VERSION ""

NS_ :

BS_:

BU_: XXX

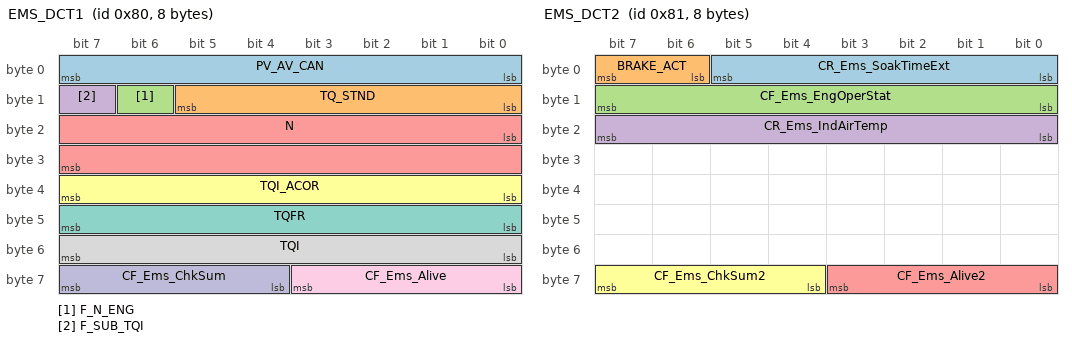
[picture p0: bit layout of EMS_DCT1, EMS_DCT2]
BO_ 128 EMS_DCT1: 8 XXX
    SG_ PV_AV_CAN : 0|8@1+ (0.3906,0) [0|99.603] "%" XXX
    SG_ TQ_STND : 8|6@1+ (10,0) [0|630] "Nm" XXX
    SG_ F_N_ENG : 14|1@1+ (1,0) [0|1] "" XXX
    SG_ F_SUB_TQI : 15|1@1+ (1,0) [0|1] "" XXX
    SG_ N : 16|16@1+ (0.25,0) [0|16383.8] "rpm" XXX
    SG_ TQI_ACOR : 32|8@1+ (0.390625,0) [0|99.6094] "%" XXX
    SG_ TQFR : 40|8@1+ (0.390625,0) [0|99.6094] "%" XXX
    SG_ TQI : 48|8@1+ (0.390625,0) [0|99.6094] "%" XXX
    SG_ CF_Ems_Alive : 56|4@1+ (1,0) [0|15] "" XXX
    SG_ CF_Ems_ChkSum : 60|4@1+ (1,0) [0|15] "" XXX

BO_ 129 EMS_DCT2: 8 XXX
    SG_ CR_Ems_SoakTimeExt : 0|6@1+ (5,0) [0|315] "Min" XXX
    SG_ BRAKE_ACT : 6|2@1+ (1,0) [0|3] "" XXX
    SG_ CF_Ems_EngOperStat : 8|8@1+ (1,0) [0|255] "" XXX
    SG_ CR_Ems_IndAirTemp : 16|8@1+ (0.75,-48) [-48|143.25] "" XXX
    SG_ CF_Ems_Alive2 : 56|4@1+ (1,0) [0|15] "" XXX
    SG_ CF_Ems_ChkSum2 : 60|4@1+ (1,0) [0|15] "" XXX

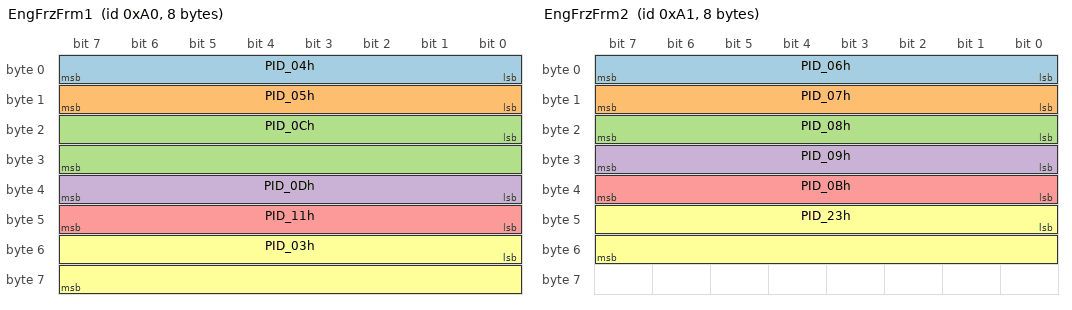
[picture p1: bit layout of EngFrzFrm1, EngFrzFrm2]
BO_ 160 EngFrzFrm1: 8 XXX
    SG_ PID_04h : 0|8@1+ (0.392157,0) [0|100] "%" XXX
    SG_ PID_05h : 8|8@1+ (1,-40) [-40|215] "" XXX
    SG_ PID_0Ch : 16|16@1+ (0.25,0) [0|16383.8] "rpm" XXX
    SG_ PID_0Dh : 32|8@1+ (1,0) [0|255] "km/h" XXX
    SG_ PID_11h : 40|8@1+ (0.392157,0) [0|100] "%" XXX
    SG_ PID_03h : 48|16@1+ (1,0) [0|65535] "" XXX

BO_ 161 EngFrzFrm2: 8 XXX
    SG_ PID_06h : 0|8@1+ (0.78125,-100) [-100|99.22] "%" XXX
    SG_ PID_07h : 8|8@1+ (0.78125,-100) [-100|99.22] "%" XXX
    SG_ PID_08h : 16|8@1+ (0.78125,-100) [-100|99.22] "%" XXX
    SG_ PID_09h : 24|8@1+ (0.78125,-100) [-100|99.22] "%" XXX
    SG_ PID_0Bh : 32|8@1+ (1,0) [0|255] "kPa" XXX
    SG_ PID_23h : 40|16@1+ (10,0) [0|655350] "kPa" XXX

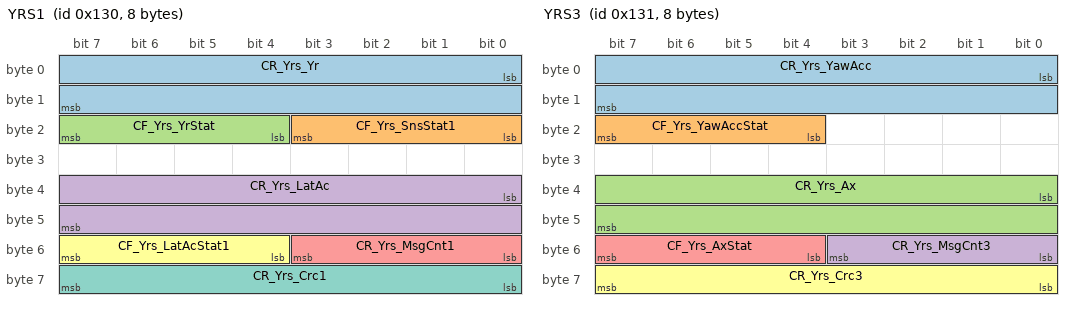
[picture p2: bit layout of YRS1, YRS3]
BO_ 304 YRS1: 8 XXX
    SG_ CR_Yrs_Yr : 0|16@1+ (0.005,-163.84) [-163.84|163.83] "" XXX
    SG_ CF_Yrs_SnsStat1 : 16|4@1+ (1,0) [0|15] "" XXX
    SG_ CF_Yrs_YrStat : 20|4@1+ (1,0) [0|15] "" XXX
    SG_ CR_Yrs_LatAc : 32|16@1+ (0.000127465,-4.17677) [-4.17677|4.17652] "g" XXX
    SG_ CR_Yrs_MsgCnt1 : 48|4@1+ (1,0) [0|15] "" XXX
    SG_ CF_Yrs_LatAcStat1 : 52|4@1+ (1,0) [0|15] "" XXX
    SG_ CR_Yrs_Crc1 : 56|8@1+ (1,0) [0|255] "" XXX

BO_ 305 YRS3: 8 XXX
    SG_ CR_Yrs_YawAcc : 0|16@1+ (0.125,-4096) [-4096|4095.75] "" XXX
    SG_ CF_Yrs_YawAccStat : 20|4@1+ (1,0) [0|15] "" XXX
    SG_ CR_Yrs_Ax : 32|16@1+ (0.000127465,-4.17677) [-4.17677|4.17652] "g" XXX
    SG_ CR_Yrs_MsgCnt3 : 48|4@1+ (1,0) [0|15] "" XXX
    SG_ CF_Yrs_AxStat : 52|4@1+ (1,0) [0|15] "" XXX
    SG_ CR_Yrs_Crc3 : 56|8@1+ (1,0) [0|255] "" XXX

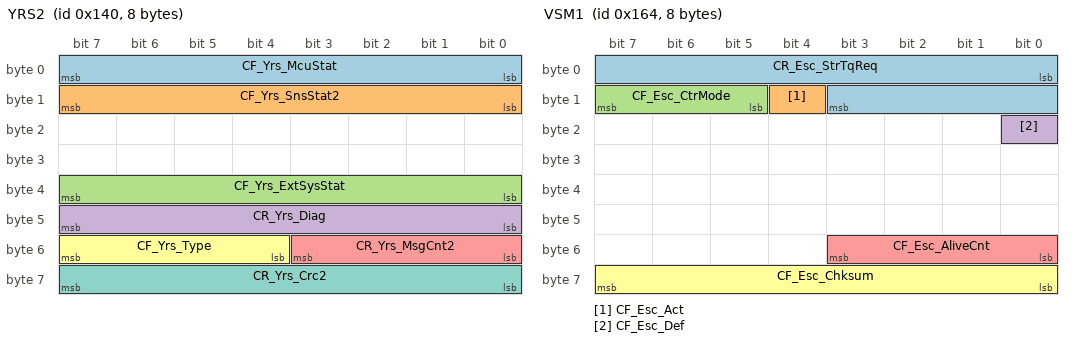
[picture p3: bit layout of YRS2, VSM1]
BO_ 320 YRS2: 8 XXX
    SG_ CF_Yrs_McuStat : 0|8@1+ (1,0) [0|255] "" XXX
    SG_ CF_Yrs_SnsStat2 : 8|8@1+ (1,0) [0|255] "" XXX
    SG_ CF_Yrs_ExtSysStat : 32|8@1+ (1,0) [0|255] "" XXX
    SG_ CR_Yrs_Diag : 40|8@1+ (1,0) [0|255] "" XXX
    SG_ CR_Yrs_MsgCnt2 : 48|4@1+ (1,0) [0|15] "" XXX
    SG_ CF_Yrs_Type : 52|4@1+ (1,0) [0|15] "" XXX
    SG_ CR_Yrs_Crc2 : 56|8@1+ (1,0) [0|255] "" XXX

BO_ 339 TCS1: 8 XXX
    SG_ TCS_REQ : 0|1@1+ (1,0) [0|1] "" XXX
    SG_ MSR_C_REQ : 1|1@1+ (1,0) [0|1] "" XXX
    SG_ TCS_PAS : 2|1@1+ (1,0) [0|1] "" XXX
    SG_ TCS_GSC : 3|1@1+ (1,0) [0|1] "" XXX
    SG_ CF_Esc_LimoInfo : 4|2@1+ (1,0) [0|3] "" XXX
    SG_ ABS_DIAG : 6|1@1+ (1,0) [0|1] "" XXX
    SG_ ABS_DEF : 7|1@1+ (1,0) [0|1] "" XXX
    SG_ TCS_DEF : 8|1@1+ (1,0) [0|1] "" XXX
    SG_ TCS_CTL : 9|1@1+ (1,0) [0|1] "" XXX
    SG_ ABS_ACT : 10|1@1+ (1,0) [0|1] "" XXX
    SG_ EBD_DEF : 11|1@1+ (1,0) [0|1] "" XXX
    SG_ ESP_PAS : 12|1@1+ (1,0) [0|1] "" XXX
    SG_ ESP_DEF : 13|1@1+ (1,0) [0|1] "" XXX
    SG_ ESP_CTL : 14|1@1+ (1,0) [0|1] "" XXX
    SG_ TCS_MFRN : 15|1@1+ (1,0) [0|1] "" XXX
    SG_ DBC_CTL : 16|1@1+ (1,0) [0|1] "" XXX
    SG_ DBC_PAS : 17|1@1+ (1,0) [0|1] "" XXX
    SG_ DBC_DEF : 18|1@1+ (1,0) [0|1] "" XXX
    SG_ HAC_CTL : 19|1@1+ (1,0) [0|1] "" XXX
    SG_ HAC_PAS : 20|1@1+ (1,0) [0|1] "" XXX
    SG_ HAC_DEF : 21|1@1+ (1,0) [0|1] "" XXX
    SG_ ESS_STAT : 22|2@1+ (1,0) [0|3] "" XXX
    SG_ TQI_TCS : 24|8@1+ (0.390625,0) [0|99.6094] "%" XXX
    SG_ TQI_MSR : 32|8@1+ (0.390625,0) [0|99.6094] "%" XXX
    SG_ TQI_SLW_TCS : 40|8@1+ (0.390625,0) [0|99.6094] "%" XXX
    SG_ CF_Esc_BrkCtl : 48|1@1+ (1,0) [0|1] "" XXX
    SG_ ESC_OFF_STEP : 49|2@1+ (1,0) [0|3] "" XXX
    SG_ _4WD_Status : 51|1@1+ (1,0) [0|1] "" XXX
    SG_ AliveCounter_TCS1 : 52|4@1+ (1,0) [0|1] "" XXX
    SG_ CheckSum_TCS1 : 56|8@1+ (1,0) [0|1] "" XXX

BO_ 356 VSM1: 8 XXX
    SG_ CR_Esc_StrTqReq : 0|12@1+ (0.01,-20.48) [-20.48|20.47] "Nm" XXX
    SG_ CF_Esc_Act : 12|1@1+ (1,0) [0|1] "" XXX
    SG_ CF_Esc_CtrMode : 13|3@1+ (1,0) [0|7] "" XXX
    SG_ CF_Esc_Def : 16|1@1+ (1,0) [0|1] "" XXX
    SG_ CF_Esc_AliveCnt : 48|4@1+ (1,0) [0|15] "" XXX
    SG_ CF_Esc_Chksum : 56|8@1+ (1,0) [0|255] "" XXX

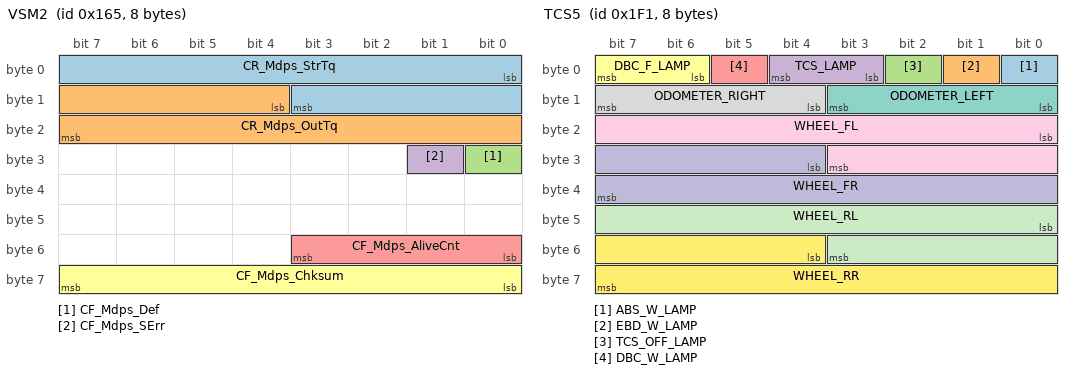
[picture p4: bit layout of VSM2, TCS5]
BO_ 357 VSM2: 8 XXX
    SG_ CR_Mdps_StrTq : 0|12@1+ (0.01,-20.48) [-20.48|20.47] "Nm" XXX
    SG_ CR_Mdps_OutTq : 12|12@1+ (0.1,-204.8) [-204.8|204.7] "" XXX
    SG_ CF_Mdps_Def : 24|1@1+ (1,0) [0|1] "" XXX
    SG_ CF_Mdps_SErr : 25|1@1+ (1,0) [0|1] "" XXX
    SG_ CF_Mdps_AliveCnt : 48|4@1+ (1,0) [0|15] "" XXX
    SG_ CF_Mdps_Chksum : 56|8@1+ (1,0) [0|255] "" XXX

BO_ 399 EMS_H2: 8 XXX
    SG_ R_TqAcnApvC : 0|8@1+ (0.2,0) [0|51] "Nm" XXX
    SG_ R_PAcnC : 8|8@1+ (125,0) [0|31875] "hPa" XXX
    SG_ TQI_B : 16|8@1+ (0.390625,0) [0|99.6094] "%" XXX
    SG_ SLD_VS : 24|8@1+ (1,0) [0|255] "km/h" XXX
    SG_ CF_CdaStat : 32|3@1+ (1,0) [0|7] "" XXX
    SG_ CF_Ems_IsgStat : 35|3@1+ (1,0) [0|7] "" XXX
    SG_ CF_Ems_OilChg : 38|1@1+ (1,0) [0|1] "" XXX
    SG_ CF_Ems_EtcLimpMod : 39|1@1+ (1,0) [0|1] "" XXX
    SG_ R_NEngIdlTgC : 40|8@1+ (10,0) [0|2550] "rpm" XXX
    SG_ CF_Ems_UpTarGr : 48|1@1+ (1,0) [0|1] "" XXX
    SG_ CF_Ems_DownTarGr : 49|1@1+ (1,0) [0|1] "" XXX
    SG_ CF_Ems_DesCurGr : 50|4@1+ (1,0) [0|15] "" XXX
    SG_ CF_Ems_SldAct : 54|1@1+ (1,0) [0|1] "" XXX
    SG_ CF_Ems_SldPosAct : 55|1@1+ (1,0) [0|1] "" XXX
    SG_ CF_Ems_HPresStat : 56|1@1+ (1,0) [0|1] "" XXX
    SG_ CF_Ems_IsgBuz : 57|1@1+ (1,0) [0|1] "" XXX
    SG_ CF_Ems_IdlStpFCO : 58|1@1+ (1,0) [0|1] "" XXX
    SG_ CF_Ems_FCopen : 59|1@1+ (1,0) [0|1] "" XXX
    SG_ CF_Ems_ActEcoAct : 60|1@1+ (1,0) [0|1] "" XXX
    SG_ CF_Ems_EngRunNorm : 61|1@1+ (1,0) [0|1] "" XXX
    SG_ CF_Ems_IsgStat2 : 62|2@1+ (2,0) [0|3] "" XXX

BO_ 497 TCS5: 8 XXX
    SG_ ABS_W_LAMP : 0|1@1+ (1,0) [0|1] "" XXX
    SG_ EBD_W_LAMP : 1|1@1+ (1,0) [0|1] "" XXX
    SG_ TCS_OFF_LAMP : 2|1@1+ (1,0) [0|1] "" XXX
    SG_ TCS_LAMP : 3|2@1+ (1,0) [0|3] "" XXX
    SG_ DBC_W_LAMP : 5|1@1+ (1,0) [0|1] "" XXX
    SG_ DBC_F_LAMP : 6|2@1+ (1,0) [0|3] "" XXX
    SG_ ODOMETER_LEFT : 8|4@1+ (1,0) [0|15] "m" XXX
    SG_ ODOMETER_RIGHT : 12|4@1+ (1,0) [0|15] "m" XXX
    SG_ WHEEL_FL : 16|12@1+ (0.125,0) [0|511.875] "km/h" XXX
    SG_ WHEEL_FR : 28|12@1+ (0.125,0) [0|511.875] "km/h" XXX
    SG_ WHEEL_RL : 40|12@1+ (0.125,0) [0|511.875] "km/h" XXX
    SG_ WHEEL_RR : 52|12@1+ (0.125,0) [0|511.875] "km/h" XXX

BO_ 544 ESP2: 8 XXX
    SG_ LAT_ACCEL : 0|11@1+ (0.01,-10.23) [-10.23|10.24] "m/s^2" XXX
    SG_ ESP2_AliveCounter_LSB : 11|3@1+ (1,0) [0|7] "" XXX
    SG_ LAT_ACCEL_STAT : 14|1@1+ (1,0) [0|1] "" XXX
    SG_ LAT_ACCEL_DIAG : 15|1@1+ (1,0) [0|1] "" XXX
    SG_ LONG_ACCEL : 16|11@1+ (0.01,-10.23) [-10.23|10.24] "m/s^2" XXX
    SG_ ESP2_AliveCounter_MSB : 27|1@1+ (1,0) [0|1] "" XXX
    SG_ ESP2_Checksum_LSB : 28|2@1+ (1,0) [0|3] "" XXX
    SG_ LONG_ACCEL_STAT : 30|1@1+ (1,0) [0|1] "" XXX
    SG_ LONG_ACCEL_DIAG : 31|1@1+ (1,0) [0|1] "" XXX
    SG_ CYL_PRES : 32|12@1+ (0.1,0) [0|409.5] "Bar" XXX
    SG_ ESP12_Checksum_MSB : 44|2@1+ (1,0) [0|3] "" XXX
    SG_ CYL_PRES_STAT : 46|1@1+ (1,0) [0|1] "" XXX
    SG_ CYL_PRESS_DIAG : 47|1@1+ (1,0) [0|1] "" XXX
    SG_ YAW_RATE : 48|13@1+ (0.01,-40.95) [-40.95|40.96] "" XXX
    SG_ CYL_PRES_FLAG : 61|1@1+ (1,0) [0|1] "" XXX
    SG_ YAW_RATE_STAT : 62|1@1+ (1,0) [0|1] "" XXX
    SG_ YAW_RATE_DIAG : 63|1@1+ (1,0) [0|1] "" XXX

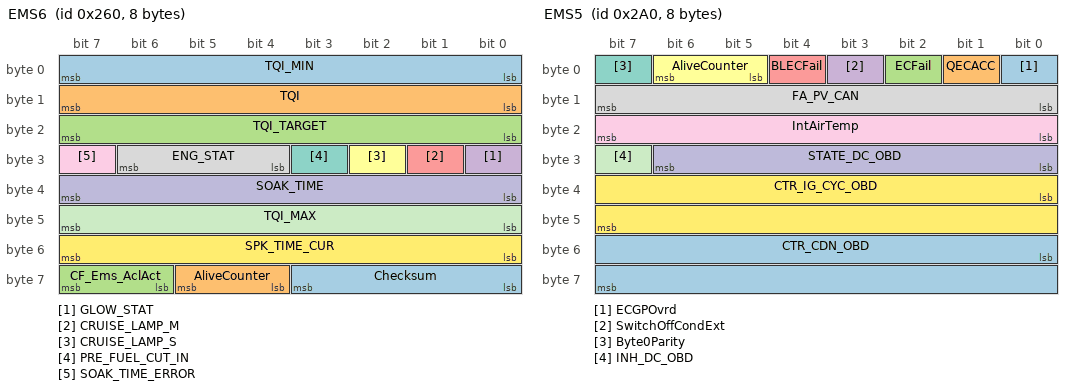
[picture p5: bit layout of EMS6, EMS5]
BO_ 608 EMS6: 8 XXX
    SG_ TQI_MIN : 0|8@1+ (0.390625,0) [0|99.6094] "%" XXX
    SG_ TQI : 8|8@1+ (0.390625,0) [0|99.6094] "%" XXX
    SG_ TQI_TARGET : 16|8@1+ (0.390625,0) [0|99.6094] "%" XXX
    SG_ GLOW_STAT : 24|1@1+ (1,0) [0|1] "" XXX
    SG_ CRUISE_LAMP_M : 25|1@1+ (1,0) [0|1] "" XXX
    SG_ CRUISE_LAMP_S : 26|1@1+ (1,0) [0|1] "" XXX
    SG_ PRE_FUEL_CUT_IN : 27|1@1+ (1,0) [0|1] "" XXX
    SG_ ENG_STAT : 28|3@1+ (1,0) [0|7] "" XXX
    SG_ SOAK_TIME_ERROR : 31|1@1+ (1,0) [0|1] "" XXX
    SG_ SOAK_TIME : 32|8@1+ (1,0) [0|255] "Min" XXX
    SG_ TQI_MAX : 40|8@1+ (0.390625,0) [0|99.6094] "%" XXX
    SG_ SPK_TIME_CUR : 48|8@1+ (0.375,-35.625) [-35.625|60] "" XXX
    SG_ Checksum : 56|4@1+ (1,0) [0|15] "" XXX
    SG_ AliveCounter : 60|2@1+ (1,0) [0|3] "" XXX
    SG_ CF_Ems_AclAct : 62|2@1+ (1,0) [0|3] "" XXX

BO_ 672 EMS5: 8 XXX
    SG_ ECGPOvrd : 0|1@1+ (1,0) [0|1] "" XXX
    SG_ QECACC : 1|1@1+ (1,0) [0|1] "" XXX
    SG_ ECFail : 2|1@1+ (1,0) [0|1] "" XXX
    SG_ SwitchOffCondExt : 3|1@1+ (1,0) [0|1] "" XXX
    SG_ BLECFail : 4|1@1+ (1,0) [0|1] "" XXX
    SG_ AliveCounter : 5|2@1+ (1,0) [0|3] "" XXX
    SG_ Byte0Parity : 7|1@1+ (1,0) [0|1] "" XXX
    SG_ FA_PV_CAN : 8|8@1+ (0.3906,0) [0|99.2] "%" XXX
    SG_ IntAirTemp : 16|8@1+ (0.75,-48) [-48|143.25] "" XXX
    SG_ STATE_DC_OBD : 24|7@1+ (1,0) [0|127] "" XXX
    SG_ INH_DC_OBD : 31|1@1+ (1,0) [0|1] "" XXX
    SG_ CTR_IG_CYC_OBD : 32|16@1+ (1,0) [0|65535] "" XXX
    SG_ CTR_CDN_OBD : 48|16@1+ (1,0) [0|65535] "" XXX

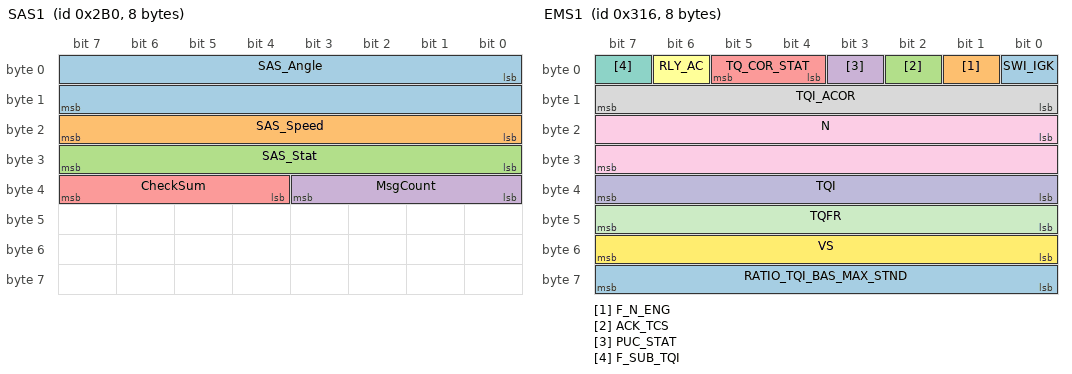
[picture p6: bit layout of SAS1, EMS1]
BO_ 688 SAS1: 8 XXX
    SG_ SAS_Angle : 0|16@1- (0.1,0) [-3276.8|3276.7] "Deg" XXX
    SG_ SAS_Speed : 16|8@1+ (4,0) [0|1016] "" XXX
    SG_ SAS_Stat : 24|8@1+ (1,0) [0|255] "" XXX
    SG_ MsgCount : 32|4@1+ (1,0) [0|15] "" XXX
    SG_ CheckSum : 36|4@1+ (1,0) [0|15] "" XXX

BO_ 790 EMS1: 8 XXX
    SG_ SWI_IGK : 0|1@1+ (1,0) [0|1] "" XXX
    SG_ F_N_ENG : 1|1@1+ (1,0) [0|1] "" XXX
    SG_ ACK_TCS : 2|1@1+ (1,0) [0|1] "" XXX
    SG_ PUC_STAT : 3|1@1+ (1,0) [0|1] "" XXX
    SG_ TQ_COR_STAT : 4|2@1+ (1,0) [0|3] "" XXX
    SG_ RLY_AC : 6|1@1+ (1,0) [0|1] "" XXX
    SG_ F_SUB_TQI : 7|1@1+ (1,0) [0|1] "" XXX
    SG_ TQI_ACOR : 8|8@1+ (0.390625,0) [0|99.6094] "%" XXX
    SG_ N : 16|16@1+ (0.25,0) [0|16383.8] "rpm" XXX
    SG_ TQI : 32|8@1+ (0.390625,0) [0|99.6094] "%" XXX
    SG_ TQFR : 40|8@1+ (0.390625,0) [0|99.6094] "%" XXX
    SG_ VS : 48|8@1+ (1,0) [0|254] "km/h" XXX
    SG_ RATIO_TQI_BAS_MAX_STND : 56|8@1+ (0.0078,0) [0|2] "" XXX

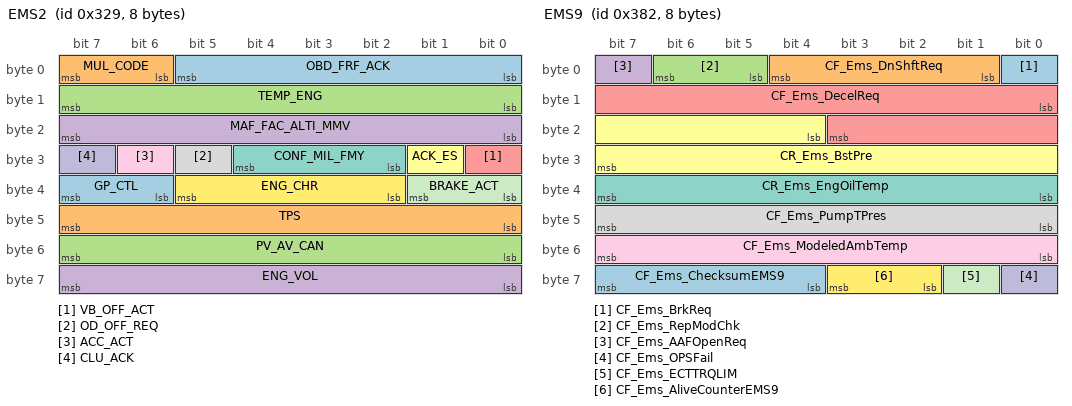
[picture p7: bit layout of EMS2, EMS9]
BO_ 809 EMS2: 8 XXX
    SG_ OBD_FRF_ACK : 0|6@1+ (1,0) [0|63] "" XXX
    SG_ MUL_CODE : 6|2@1+ (1,0) [0|3] "" XXX
    SG_ TEMP_ENG : 8|8@1+ (0.75,-48) [-48|143.25] "" XXX
    SG_ MAF_FAC_ALTI_MMV : 16|8@1+ (0.00781,0) [0|1.99155] "" XXX
    SG_ VB_OFF_ACT : 24|1@1+ (1,0) [0|1] "" XXX
    SG_ ACK_ES : 25|1@1+ (1,0) [0|1] "" XXX
    SG_ CONF_MIL_FMY : 26|3@1+ (1,0) [0|7] "" XXX
    SG_ OD_OFF_REQ : 29|1@1+ (1,0) [0|1] "" XXX
    SG_ ACC_ACT : 30|1@1+ (1,0) [0|1] "" XXX
    SG_ CLU_ACK : 31|1@1+ (1,0) [0|1] "" XXX
    SG_ BRAKE_ACT : 32|2@1+ (1,0) [0|3] "" XXX
    SG_ ENG_CHR : 34|4@1+ (1,0) [0|15] "" XXX
    SG_ GP_CTL : 38|2@1+ (1,0) [0|3] "" XXX
    SG_ TPS : 40|8@1+ (0.469484,-15.0235) [-15.0235|104.695] "%" XXX
    SG_ PV_AV_CAN : 48|8@1+ (0.3906,0) [0|99.603] "%" XXX
    SG_ ENG_VOL : 56|8@1+ (0.1,0) [0|25.5] "liter" XXX

BO_ 848 FATC: 8 XXX
    SG_ CR_Fatc_TqAcnOut : 0|8@1+ (0.2,0) [0|50.8] "Nm" XXX
    SG_ CF_Fatc_AcnRqSwi : 8|1@1+ (1,0) [0|1] "" XXX
    SG_ CF_Fatc_AcnCltEnRq : 9|1@1+ (1,0) [0|1] "" XXX
    SG_ CF_Fatc_EcvFlt : 10|1@1+ (1,0) [0|1] "" XXX
    SG_ CF_Fatc_BlwrOn : 11|1@1+ (1,0) [0|1] "" XXX
    SG_ CF_FATC_Iden : 12|2@1+ (1,0) [0|3] "" XXX
    SG_ CF_Fatc_BlwrMax : 14|1@1+ (1,0) [0|1] "" XXX
    SG_ CF_Fatc_EngStartReq : 15|1@1+ (1,0) [0|1] "" XXX
    SG_ CF_Fatc_IsgStopReq : 16|1@1+ (1,0) [0|1] "" XXX
    SG_ CF_Fatc_CtrInf : 17|3@1+ (1,0) [0|7] "" XXX
    SG_ CF_Fatc_MsgCnt : 20|4@1+ (1,0) [0|15] "" XXX
    SG_ CR_Fatc_OutTemp : 24|8@1+ (0.5,-40) [-40|60] "" XXX
    SG_ CR_Fatc_OutTempSns : 32|8@1+ (0.5,-40) [-40|60] "" XXX
    SG_ CF_Fatc_Compload : 40|3@1+ (1,0) [0|7] "" XXX
    SG_ CF_Fatc_ActiveEco : 43|1@1+ (1,0) [0|1] "" XXX
    SG_ CF_Fatc_AutoActivation : 44|1@1+ (1,0) [0|1] "" XXX
    SG_ CF_Fatc_DefSw : 45|1@1+ (1,0) [0|1] "" XXX
    SG_ CF_Fatc_PtcRlyStat : 46|1@1+ (1,0) [0|1] "" XXX
    SG_ CF_Fatc_ChkSum : 56|8@1+ (1,0) [0|255] "" XXX

BO_ 880 TCU3: 8 XXX
    SG_ N_TGT_LUP : 0|8@1+ (10,500) [500|3040] "rpm" XXX
    SG_ SLOPE_TCU : 8|6@1+ (0.5,-16) [-16|15.5] "%" XXX
    SG_ CF_Tcu_InhCda : 14|1@1+ (1,0) [0|1] "" XXX
    SG_ CF_Tcu_IsgInhib : 15|1@1+ (1,0) [0|1] "" XXX
    SG_ CF_Tcu_BkeOnReq : 16|2@1+ (1,0) [0|3] "" XXX
    SG_ CF_Tcu_NCStat : 18|2@1+ (1,0) [0|3] "" XXX
    SG_ CF_Tcu_TarGr : 20|4@1+ (1,0) [0|15] "" XXX
    SG_ CF_Tcu_ShfPatt : 24|4@1+ (1,0) [0|15] "" XXX
    SG_ CF_Tcu_InhVis : 28|1@1+ (1,0) [0|1] "" XXX
    SG_ CF_Tcu_PRelReq : 29|1@1+ (1,0) [0|1] "" XXX
    SG_ CF_Tcu_ITPhase : 30|1@1+ (1,0) [0|1] "" XXX
    SG_ CF_Tcu_ActEcoRdy : 31|1@1+ (1,0) [0|1] "" XXX
    SG_ CF_Tcu_TqGrdLim : 32|8@1+ (10,0) [0|2540] "Nm/s" XXX
    SG_ CR_Tcu_IsgTgtRPM : 40|8@1+ (20,0) [0|3500] "rpm" XXX
    SG_ TQI_TCU_INC : 48|8@1+ (0.390625,0) [0|99.6094] "%" XXX
    SG_ CF_Tcu_SbwPInfo : 56|1@1+ (1,0) [0|1] "" XXX
    SG_ CF_Tcu_SptRdy : 57|1@1+ (1,0) [0|1] "" XXX
    SG_ CF_Tcu_Alive3 : 58|2@1+ (1,0) [0|3] "" XXX
    SG_ CF_Tcu_ChkSum3 : 60|4@1+ (1,0) [0|15] "" XXX

BO_ 898 EMS9: 8 XXX
    SG_ CF_Ems_BrkReq : 0|1@1+ (1,0) [0|1] "" XXX
    SG_ CF_Ems_DnShftReq : 1|4@1+ (1,0) [0|14] "" XXX
    SG_ CF_Ems_RepModChk : 5|2@1+ (1,0) [0|3] "" XXX
    SG_ CF_Ems_AAFOpenReq : 7|1@1+ (1,0) [0|1] "" XXX
    SG_ CF_Ems_DecelReq : 8|12@1+ (0.001,-4.094) [-4.094|0] "m/s^2" XXX
    SG_ CR_Ems_BstPre : 20|12@1+ (1.322,0) [0|4094] "hPa" XXX
    SG_ CR_Ems_EngOilTemp : 32|8@1+ (0.75,-40) [0|254] "" XXX
    SG_ CF_Ems_PumpTPres : 40|8@1+ (3.13725,0) [0|800] "kPa" XXX
    SG_ CF_Ems_ModeledAmbTemp : 48|8@1+ (0.5,-41) [-40|60] "" XXX
    SG_ CF_Ems_OPSFail : 56|1@1+ (1,0) [0|1] "" XXX
    SG_ CF_Ems_ECTTRQLIM : 57|1@1+ (1,0) [0|1] "" XXX
    SG_ CF_Ems_AliveCounterEMS9 : 58|2@1+ (1,0) [0|3] "" XXX
    SG_ CF_Ems_ChecksumEMS9 : 60|4@1+ (1,0) [0|15] "" XXX

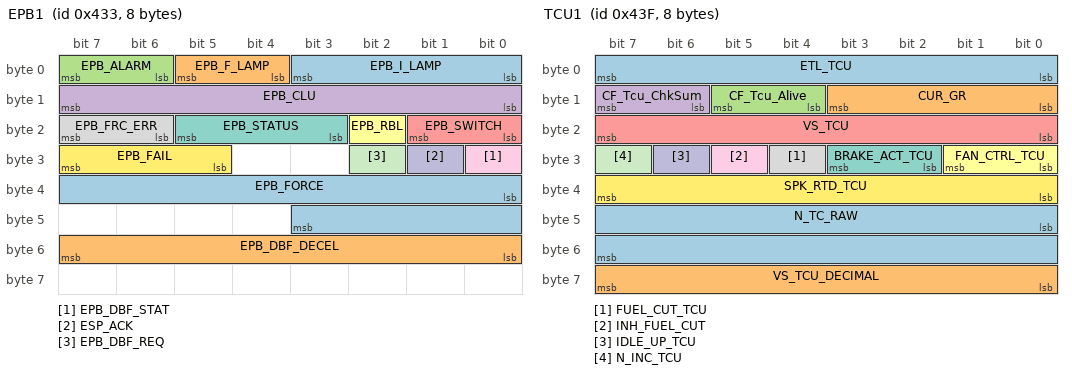
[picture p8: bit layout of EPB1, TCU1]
BO_ 1075 EPB1: 8 XXX
    SG_ EPB_I_LAMP : 0|4@1+ (1,0) [0|15] "" XXX
    SG_ EPB_F_LAMP : 4|2@1+ (1,0) [0|3] "" XXX
    SG_ EPB_ALARM : 6|2@1+ (1,0) [0|3] "" XXX
    SG_ EPB_CLU : 8|8@1+ (1,0) [0|255] "" XXX
    SG_ EPB_SWITCH : 16|2@1+ (1,0) [0|3] "" XXX
    SG_ EPB_RBL : 18|1@1+ (1,0) [0|1] "" XXX
    SG_ EPB_STATUS : 19|3@1+ (1,0) [0|7] "" XXX
    SG_ EPB_FRC_ERR : 22|2@1+ (1,0) [0|3] "" XXX
    SG_ EPB_DBF_STAT : 24|1@1+ (1,0) [0|1] "" XXX
    SG_ ESP_ACK : 25|1@1+ (1,0) [0|1] "" XXX
    SG_ EPB_DBF_REQ : 26|1@1+ (1,0) [0|1] "" XXX
    SG_ EPB_FAIL : 29|3@1+ (1,0) [0|7] "" XXX
    SG_ EPB_FORCE : 32|12@1+ (1,-1000) [-1000|3000] "" XXX
    SG_ EPB_DBF_DECEL : 48|8@1+ (0.01,0) [0|2.54] "g" XXX

BO_ 1087 TCU1: 8 XXX
    SG_ ETL_TCU : 0|8@1+ (2,0) [0|508] "Nm" XXX
    SG_ CUR_GR : 8|4@1+ (1,0) [0|15] "" XXX
    SG_ CF_Tcu_Alive : 12|2@1+ (1,0) [0|3] "" XXX
    SG_ CF_Tcu_ChkSum : 14|2@1+ (1,0) [0|3] "" XXX
    SG_ VS_TCU : 16|8@1+ (1,0) [0|254] "km/h" XXX
    SG_ FAN_CTRL_TCU : 24|2@1+ (1,0) [0|3] "" XXX
    SG_ BRAKE_ACT_TCU : 26|2@1+ (1,0) [0|3] "" XXX
    SG_ FUEL_CUT_TCU : 28|1@1+ (1,0) [0|1] "" XXX
    SG_ INH_FUEL_CUT : 29|1@1+ (1,0) [0|1] "" XXX
    SG_ IDLE_UP_TCU : 30|1@1+ (1,0) [0|1] "" XXX
    SG_ N_INC_TCU : 31|1@1+ (1,0) [0|1] "" XXX
    SG_ SPK_RTD_TCU : 32|8@1+ (0.375,-23.625) [-15|15] "" XXX
    SG_ N_TC_RAW : 40|16@1+ (0.25,0) [0|16383.5] "rpm" XXX
    SG_ VS_TCU_DECIMAL : 56|8@1+ (0.0078125,0) [0|0.992188] "km/h" XXX

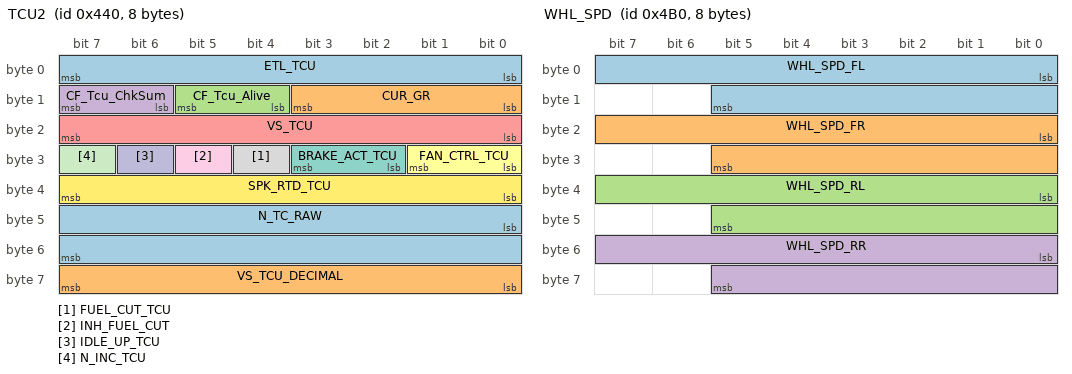
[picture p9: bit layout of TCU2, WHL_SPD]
BO_ 1088 TCU2: 8 XXX
    SG_ ETL_TCU : 0|8@1+ (2,0) [0|508] "Nm" XXX
    SG_ CUR_GR : 8|4@1+ (1,0) [0|15] "" XXX
    SG_ CF_Tcu_Alive : 12|2@1+ (1,0) [0|3] "" XXX
    SG_ CF_Tcu_ChkSum : 14|2@1+ (1,0) [0|3] "" XXX
    SG_ VS_TCU : 16|8@1+ (1,0) [0|254] "km/h" XXX
    SG_ FAN_CTRL_TCU : 24|2@1+ (1,0) [0|3] "" XXX
    SG_ BRAKE_ACT_TCU : 26|2@1+ (1,0) [0|3] "" XXX
    SG_ FUEL_CUT_TCU : 28|1@1+ (1,0) [0|1] "" XXX
    SG_ INH_FUEL_CUT : 29|1@1+ (1,0) [0|1] "" XXX
    SG_ IDLE_UP_TCU : 30|1@1+ (1,0) [0|1] "" XXX
    SG_ N_INC_TCU : 31|1@1+ (1,0) [0|1] "" XXX
    SG_ SPK_RTD_TCU : 32|8@1+ (0.375,-23.625) [-15|15] "" XXX
    SG_ N_TC_RAW : 40|16@1+ (0.25,0) [0|16383.5] "rpm" XXX
    SG_ VS_TCU_DECIMAL : 56|8@1+ (0.0078125,0) [0|0.992188] "km/h" XXX

BO_ 1200 WHL_SPD: 8 XXX
    SG_ WHL_SPD_FL : 0|14@1+ (0.03125,0) [0|511.969] "km/h" XXX
    SG_ WHL_SPD_FR : 16|14@1+ (0.03125,0) [0|511.969] "km/h" XXX
    SG_ WHL_SPD_RL : 32|14@1+ (0.03125,0) [0|511.969] "km/h" XXX
    SG_ WHL_SPD_RR : 48|14@1+ (0.03125,0) [0|511.969] "km/h" XXX

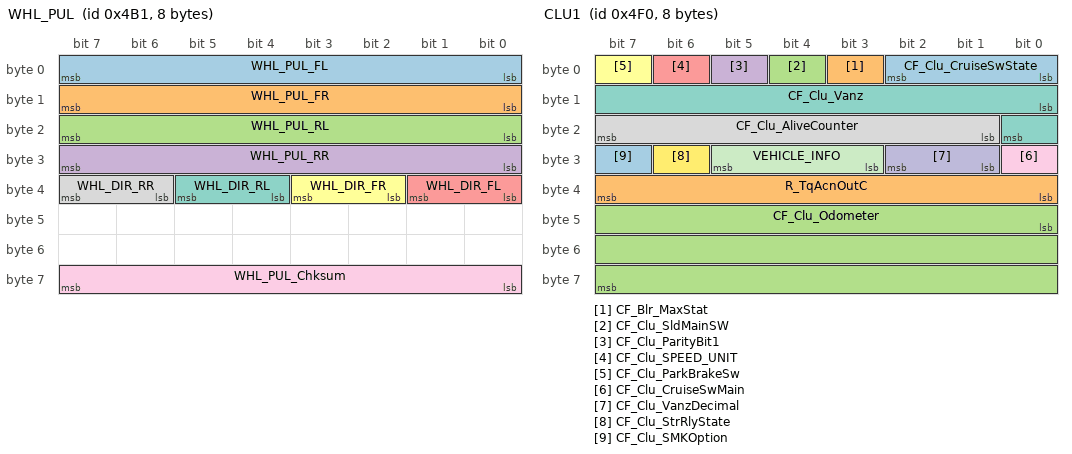
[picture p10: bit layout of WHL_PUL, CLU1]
BO_ 1201 WHL_PUL: 8 XXX
    SG_ WHL_PUL_FL : 0|8@1+ (0.5,0) [0|127.5] "pulse count" XXX
    SG_ WHL_PUL_FR : 8|8@1+ (0.5,0) [0|127.5] "pulse count" XXX
    SG_ WHL_PUL_RL : 16|8@1+ (0.5,0) [0|127.5] "pulse count" XXX
    SG_ WHL_PUL_RR : 24|8@1+ (0.5,0) [0|127.5] "pulse count" XXX
    SG_ WHL_DIR_FL : 32|2@1+ (1,0) [0|3] "" XXX
    SG_ WHL_DIR_FR : 34|2@1+ (1,0) [0|3] "" XXX
    SG_ WHL_DIR_RL : 36|2@1+ (1,0) [0|3] "" XXX
    SG_ WHL_DIR_RR : 38|2@1+ (1,0) [0|3] "" XXX
    SG_ WHL_PUL_Chksum : 56|8@1+ (1,0) [0|255] "" XXX

BO_ 1264 CLU1: 8 XXX
    SG_ CF_Clu_CruiseSwState : 0|3@1+ (1,0) [0|7] "" XXX
    SG_ CF_Blr_MaxStat : 3|1@1+ (1,0) [0|1] "" XXX
    SG_ CF_Clu_SldMainSW : 4|1@1+ (1,0) [0|1] "" XXX
    SG_ CF_Clu_ParityBit1 : 5|1@1+ (1,0) [0|1] "pulse count" XXX
    SG_ CF_Clu_SPEED_UNIT : 6|1@1+ (1,0) [0|1] "" XXX
    SG_ CF_Clu_ParkBrakeSw : 7|1@1+ (1,0) [0|1] "" XXX
    SG_ CF_Clu_Vanz : 8|9@1+ (0.5,0) [0|255.5] "km/h or MPH" XXX
    SG_ CF_Clu_AliveCounter : 17|7@1+ (1,0) [0|127] "" XXX
    SG_ CF_Clu_CruiseSwMain : 24|1@1+ (1,0) [0|1] "" XXX
    SG_ CF_Clu_VanzDecimal : 25|2@1+ (1,0) [0|0.375] "" XXX
    SG_ VEHICLE_INFO : 27|3@1+ (1,0) [0|7] "" XXX
    SG_ CF_Clu_StrRlyState : 30|1@1+ (1,0) [0|1] "" XXX
    SG_ CF_Clu_SMKOption : 31|1@1+ (1,0) [0|1] "" XXX
    SG_ R_TqAcnOutC : 32|8@1+ (1,0) [0|51] "Nm" XXX
    SG_ CF_Clu_Odometer : 40|24@1+ (0.1,0) [0|1.67772e+006] "km" XXX

BO_ 1265 CLU3: 8 XXX
    SG_ CF_Clu_AcnRqSwi : 0|1@1+ (1,0) [0|1] "" XXX
    SG_ CF_Clu_AcnCltEnRq : 1|1@1+ (1,0) [0|1] "" XXX
    SG_ CF_Clu_RefDetMod : 2|1@1+ (1,0) [0|1] "" XXX
    SG_ CF_Clu_DefoggerRly : 5|1@1+ (1,0) [0|1] "" XXX
    SG_ CF_Clu_LowfuelWarn : 16|2@1+ (1,0) [0|3] "" XXX
    SG_ CF_Clu_SportsModeSwi : 18|2@1+ (1,0) [0|3] "" XXX
    SG_ CF_Clu_ALightStat : 20|1@1+ (1,0) [0|1] "" XXX
    SG_ CF_Clu_FrtFog : 21|1@1+ (1,0) [0|1] "" XXX
    SG_ CF_Clu_DetentOut : 22|1@1+ (1,0) [0|1] "" XXX
    SG_ CF_Clu_HeadLampTail : 23|1@1+ (1,0) [0|1] "" XXX
    SG_ CF_Clu_TrailerMode : 24|1@1+ (1,0) [0|1] "" XXX
    SG_ CF_Clu_DTE : 25|10@1+ (1,0) [0|1023] "" XXX
    SG_ CF_Clu_TripUnit : 35|2@1+ (1,0) [0|3] "" XXX
    SG_ CF_Clu_IsaMainSW : 37|1@1+ (1,0) [0|1] "" XXX
    SG_ CF_Clu_FlexSteerSW : 40|1@1+ (1,0) [0|1] "" XXX
    SG_ CF_Clu_AvsmCur : 41|1@1+ (1,0) [0|1] "" XXX
    SG_ CF_Clu_HudSpeedset : 42|1@1+ (1,0) [0|1] "" XXX
    SG_ CF_Clu_HudTbtSet : 43|1@1+ (1,0) [0|1] "" XXX
    SG_ CF_Clu_HudSccSet : 44|1@1+ (1,0) [0|1] "" XXX
    SG_ CF_Clu_HudLdwsSet : 45|1@1+ (1,0) [0|1] "" XXX
    SG_ CF_Clu_HudDisSet : 46|1@1+ (1,0) [0|1] "" XXX
    SG_ CF_Clu_HudFontSizeSet : 47|2@1+ (1,0) [0|3] "" XXX
    SG_ CF_Clu_HudFontColorSet : 49|2@1+ (1,0) [0|3] "" XXX
    SG_ CF_Clu_HudBrightSet : 51|2@1+ (1,0) [0|3] "" XXX
    SG_ CF_Clu_HudHeightSet : 53|2@1+ (1,0) [0|3] "" XXX
    SG_ CF_Clu_CluInfo : 55|1@1+ (1,0) [0|1] "" XXX
    SG_ CF_Clu_RheostatLevel : 56|5@1+ (1,0) [0|31] "" XXX
    SG_ CF_Clu_DrivinglampStat : 61|3@1+ (1,0) [0|7] "" XXX

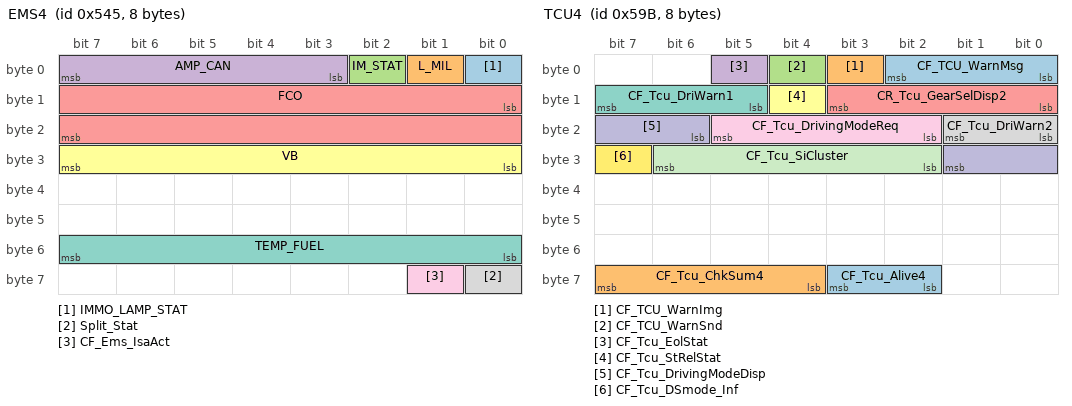
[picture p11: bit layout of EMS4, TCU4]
BO_ 1349 EMS4: 8 XXX
    SG_ IMMO_LAMP_STAT : 0|1@1+ (1,0) [0|1] "" XXX
    SG_ L_MIL : 1|1@1+ (1,0) [0|1] "" XXX
    SG_ IM_STAT : 2|1@1+ (1,0) [0|1] "" XXX
    SG_ AMP_CAN : 3|5@1+ (10.7316,458.98) [458.98|791.66] "mmHg" XXX
    SG_ FCO : 8|16@1+ (0.128,0) [0|8388.48] "ul" XXX
    SG_ VB : 24|8@1+ (0.101563,0) [0|25.8984] "V" XXX
    SG_ TEMP_FUEL : 48|8@1+ (0.75,-48) [-48|143.25] "" XXX
    SG_ Split_Stat : 56|1@1+ (1,0) [0|1] "" XXX
    SG_ CF_Ems_IsaAct : 57|1@1+ (1,0) [0|1] "" XXX

BO_ 1435 TCU4: 8 XXX
    SG_ CF_TCU_WarnMsg : 0|3@1+ (1,0) [0|7] "" XXX
    SG_ CF_TCU_WarnImg : 3|1@1+ (1,0) [0|1] "" XXX
    SG_ CF_TCU_WarnSnd : 4|1@1+ (1,0) [0|1] "" XXX
    SG_ CF_Tcu_EolStat : 5|1@1+ (1,0) [0|1] "" XXX
    SG_ CR_Tcu_GearSelDisp2 : 8|4@1+ (1,0) [0|15] "" XXX
    SG_ CF_Tcu_StRelStat : 12|1@1+ (1,0) [0|1] "" XXX
    SG_ CF_Tcu_DriWarn1 : 13|3@1+ (1,0) [0|7] "" XXX
    SG_ CF_Tcu_DriWarn2 : 16|2@1+ (1,0) [0|3] "" XXX
    SG_ CF_Tcu_DrivingModeReq : 18|4@1+ (1,0) [0|0] "" XXX
    SG_ CF_Tcu_DrivingModeDisp : 22|4@1+ (1,0) [0|0] "" XXX
    SG_ CF_Tcu_SiCluster : 26|5@1+ (1,0) [0|0] "" XXX
    SG_ CF_Tcu_DSmode_Inf : 31|1@1+ (1,0) [0|1] "" XXX
    SG_ CF_Tcu_Alive4 : 58|2@1+ (1,0) [0|3] "" XXX
    SG_ CF_Tcu_ChkSum4 : 60|4@1+ (1,0) [0|15] "" XXX

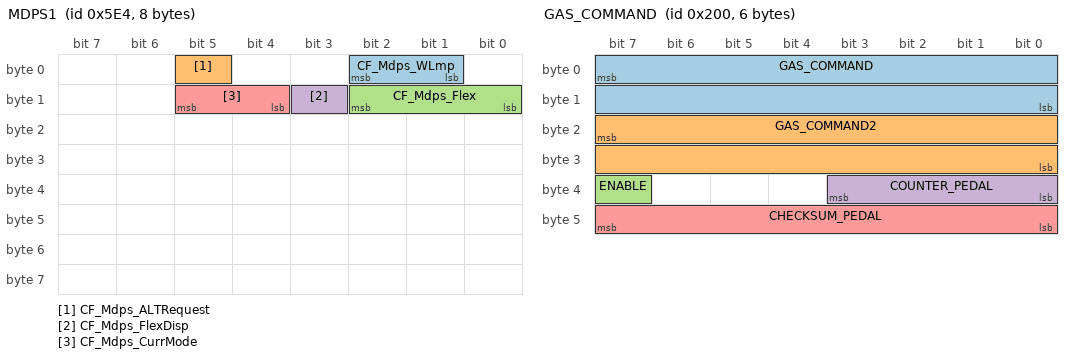
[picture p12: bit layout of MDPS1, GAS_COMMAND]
BO_ 1508 MDPS1: 8 XXX
    SG_ CF_Mdps_WLmp : 1|2@1+ (1,0) [0|3] "" XXX
    SG_ CF_Mdps_ALTRequest : 5|1@1+ (1,0) [0|1] "" XXX
    SG_ CF_Mdps_Flex : 8|3@1+ (1,0) [0|7] "" XXX
    SG_ CF_Mdps_FlexDisp : 11|1@1+ (1,0) [0|1] "" XXX
    SG_ CF_Mdps_CurrMode : 12|2@1+ (1,0) [0|3] "" XXX

BO_ 1680 CLU2: 8 XXX
    SG_ CF_Clu_IGNSw : 0|3@1+ (1,0) [0|7] "" XXX
    SG_ RKE_CMD : 3|3@1+ (1,0) [0|7] "" XXX
    SG_ CF_Clu_DrvDrSw : 6|2@1+ (1,0) [0|3] "" XXX
    SG_ CF_Clu_DrvKeyLockSw : 8|1@1+ (1,0) [0|1] "" XXX
    SG_ CF_Clu_DrvKeyUnlockSw : 9|1@1+ (1,0) [0|1] "" XXX
    SG_ PIC_Lock : 10|3@1+ (1,0) [0|7] "" XXX
    SG_ PIC_Unlock : 13|3@1+ (1,0) [0|7] "" XXX
    SG_ CF_Clu_DrvSeatBeltSw : 16|2@1+ (1,0) [0|3] "" XXX
    SG_ CF_Clu_TrunkTgSw : 18|2@1+ (1,0) [0|3] "" XXX
    SG_ CF_Clu_AstSeatBeltSw : 20|2@1+ (1,0) [0|3] "" XXX
    SG_ CF_Clu_HoodSw : 22|2@1+ (1,0) [0|3] "" XXX
    SG_ CF_Clu_TurnSigLh : 24|1@1+ (1,0) [0|1] "" XXX
    SG_ CF_Clu_TurnSigRh : 25|1@1+ (1,0) [0|1] "" XXX
    SG_ CF_Clu_LdwsLkasSW : 26|1@1+ (1,0) [0|1] "" XXX
    SG_ CF_Clu_WiperIntT : 27|3@1+ (1,0) [0|7] "" XXX
    SG_ CF_Clu_WiperIntSW : 30|1@1+ (1,0) [0|1] "" XXX
    SG_ CF_Clu_WiperLow : 31|1@1+ (1,0) [0|1] "" XXX
    SG_ CF_Clu_WiperHigh : 32|1@1+ (1,0) [0|1] "" XXX
    SG_ CF_Clu_WiperAuto : 33|1@1+ (1,0) [0|1] "" XXX
    SG_ CF_Clu_RainSnsStat : 34|3@1+ (1,0) [0|7] "" XXX
    SG_ CF_Clu_HeadLampLow : 37|1@1+ (1,0) [0|1] "" XXX
    SG_ CF_Clu_HeadLampHigh : 38|1@1+ (1,0) [0|1] "" XXX
    SG_ CF_Clu_AltLStatus : 39|1@1+ (1,0) [0|1] "" XXX
    SG_ CF_Clu_EcoDriveInf : 40|3@1+ (1,0) [0|7] "" XXX
    SG_ CF_Clu_SwiGearR : 43|2@1+ (1,0) [0|3] "" XXX
    SG_ CF_Clu_SWL_Stat : 45|3@1+ (1,0) [0|7] "" XXX
    SG_ CF_Clu_ActiveEcoSW : 48|1@1+ (1,0) [0|1] "" XXX
    SG_ CF_Clu_HazardSW : 49|1@1+ (1,0) [0|1] "" XXX
    SG_ CF_Clu_AliveCnt2 : 50|4@1+ (1,0) [0|15] "" XXX
    SG_ CF_Clu_AstDrSw : 54|2@1+ (1,0) [0|3] "" XXX
    SG_ CF_Clu_LkasDispMode : 56|2@1+ (1,0) [0|3] "" XXX
    SG_ CF_Clu_AutoLightLevel : 58|2@1+ (1,0) [0|3] "" XXX
    SG_ CF_Clu_SunRoofOpenState : 60|1@1+ (1,0) [0|1] "" XXX

BU_: XXX EON EPAS INTERCEPTOR CAN_Host STM32G474_TRQI

CM_ "GAS INTERCEPTOR and StepperServoCAN messages";

BO_ 512 GAS_COMMAND: 6 EON
  SG_ GAS_COMMAND : 7|16@0+ (0.05,-27) [0|1] "" INTERCEPTOR
  SG_ GAS_COMMAND2 : 23|16@0+ (0.1,-27) [0|1] "" INTERCEPTOR
  SG_ ENABLE : 39|1@0+ (1,0) [0|1] "" INTERCEPTOR
  SG_ COUNTER_PEDAL : 35|4@0+ (1,0) [0|15] "" INTERCEPTOR
  SG_ CHECKSUM_PEDAL : 47|8@0+ (1,0) [0|255] "" INTERCEPTOR

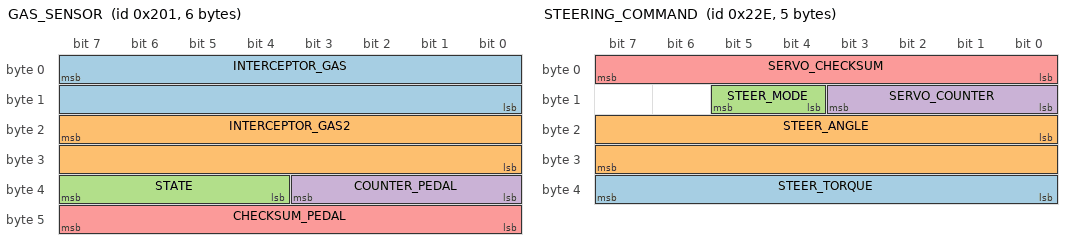
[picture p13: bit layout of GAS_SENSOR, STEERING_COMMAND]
BO_ 513 GAS_SENSOR: 6 INTERCEPTOR
  SG_ INTERCEPTOR_GAS : 7|16@0+ (0.05,-25) [0|1] "" EON
  SG_ INTERCEPTOR_GAS2 : 23|16@0+ (0.1,-25) [0|1] "" EON
  SG_ STATE : 39|4@0+ (1,0) [0|15] "" EON
  SG_ COUNTER_PEDAL : 35|4@0+ (1,0) [0|15] "" EON
  SG_ CHECKSUM_PEDAL : 47|8@0+ (1,0) [0|255] "" EON

VAL_ 513 STATE 5 "FAULT_TIMEOUT" 4 "FAULT_STARTUP" 3 "FAULT_SCE" 2 "FAULT_SEND" 1 "FAULT_BAD_CHECKSUM" 0 "NO_FAULT" ;

BO_ 558 STEERING_COMMAND: 5 EON
  SG_ STEER_TORQUE : 32|8@1- (0.125,0) [-16|15.875] "Nm" EPAS
  SG_ STEER_ANGLE : 16|16@1- (0.125,0) [-4096|4095.875] "deg" EPAS
  SG_ STEER_MODE : 12|2@1+ (1,0) [0|3] "" EPAS
  SG_ SERVO_COUNTER : 8|4@1+ (1,0) [0|15] "" EPAS
  SG_ SERVO_CHECKSUM : 0|8@1+ (1,0) [0|255] "" EPAS

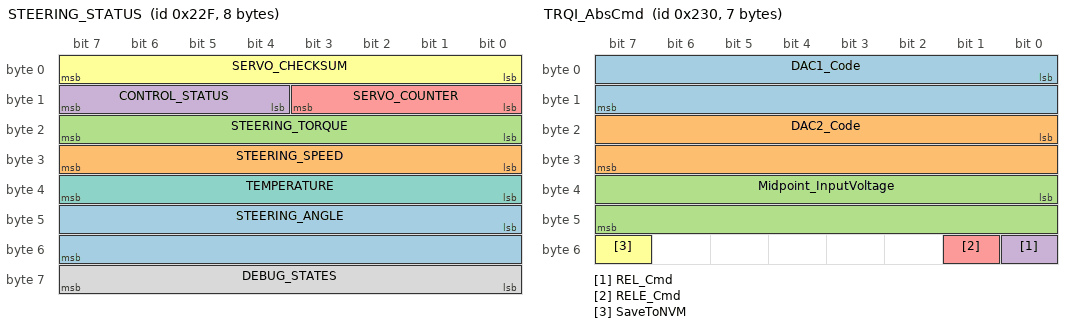
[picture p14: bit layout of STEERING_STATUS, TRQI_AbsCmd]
BO_ 559 STEERING_STATUS: 8 EPAS
  SG_ STEERING_ANGLE : 40|16@1- (0.125,0) [-4096|4095.875] "deg" EON
  SG_ STEERING_SPEED : 24|8@1- (0.015625,0) [-2|1.984375] "rev/s" EON
  SG_ STEERING_TORQUE : 16|8@1- (0.125,0) [-16|15.875] "Nm" EON
  SG_ CONTROL_STATUS : 12|4@1+ (1,0) [0|15] "" EON
  SG_ SERVO_COUNTER : 8|4@1+ (1,0) [0|15] "" EON
  SG_ SERVO_CHECKSUM : 0|8@1+ (1,0) [0|255] "" EON
  SG_ TEMPERATURE : 32|8@1+ (1,-60) [-60|195] "C" EON
  SG_ DEBUG_STATES : 56|8@1+ (1,0) [0|255] "" EON

BO_ 560 TRQI_AbsCmd: 7 CAN_Host
 SG_ DAC1_Code : 0|16@1+ (1,0) [0|4095] "code" STM32G474_TRQI
 SG_ DAC2_Code : 16|16@1+ (1,0) [0|4095] "code" STM32G474_TRQI
 SG_ Midpoint_InputVoltage : 32|16@1+ (0.001,0) [0|65.535] "V" STM32G474_TRQI
 SG_ REL_Cmd : 48|1@1+ (1,0) [0|1] "" STM32G474_TRQI
 SG_ RELE_Cmd : 49|1@1+ (1,0) [0|1] "" STM32G474_TRQI
 SG_ SaveToNVM : 55|1@1+ (1,0) [0|1] "" STM32G474_TRQI

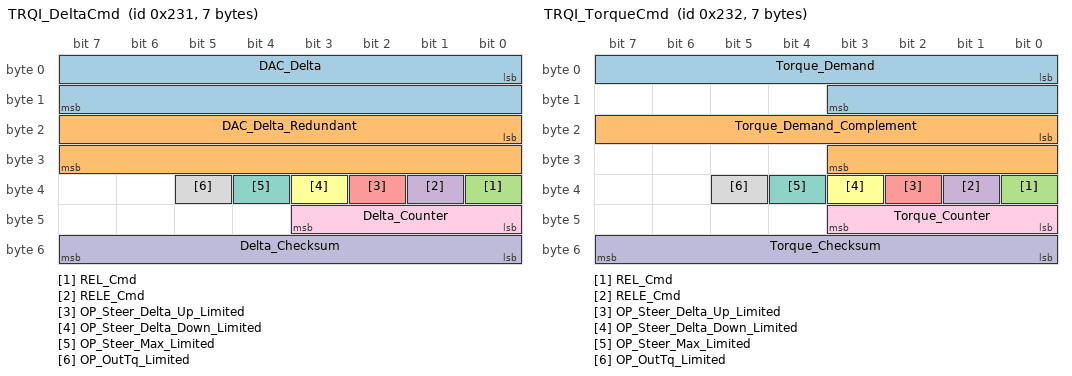
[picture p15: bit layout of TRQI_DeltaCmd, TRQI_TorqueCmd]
BO_ 561 TRQI_DeltaCmd: 7 CAN_Host
 SG_ DAC_Delta : 0|16@1- (1,0) [-2047|2047] "code" STM32G474_TRQI
 SG_ DAC_Delta_Redundant : 16|16@1- (1,0) [-2047|2047] "code" STM32G474_TRQI
 SG_ REL_Cmd : 32|1@1+ (1,0) [0|1] "" STM32G474_TRQI
 SG_ RELE_Cmd : 33|1@1+ (1,0) [0|1] "" STM32G474_TRQI
 SG_ OP_Steer_Delta_Up_Limited : 34|1@1+ (1,0) [0|1] "" STM32G474_TRQI
 SG_ OP_Steer_Delta_Down_Limited : 35|1@1+ (1,0) [0|1] "" STM32G474_TRQI
 SG_ OP_Steer_Max_Limited : 36|1@1+ (1,0) [0|1] "" STM32G474_TRQI
 SG_ OP_OutTq_Limited : 37|1@1+ (1,0) [0|1] "" STM32G474_TRQI
 SG_ Delta_Counter : 40|4@1+ (1,0) [0|15] "" STM32G474_TRQI
 SG_ Delta_Checksum : 48|8@1+ (1,0) [0|255] "" STM32G474_TRQI

BO_ 562 TRQI_TorqueCmd: 7 CAN_Host
 SG_ Torque_Demand : 0|12@1- (1,0) [-2048|2047] "Ncm" STM32G474_TRQI
 SG_ Torque_Demand_Complement : 16|12@1+ (1,0) [0|4095] "raw12" STM32G474_TRQI
 SG_ REL_Cmd : 32|1@1+ (1,0) [0|1] "" STM32G474_TRQI
 SG_ RELE_Cmd : 33|1@1+ (1,0) [0|1] "" STM32G474_TRQI
 SG_ OP_Steer_Delta_Up_Limited : 34|1@1+ (1,0) [0|1] "" STM32G474_TRQI
 SG_ OP_Steer_Delta_Down_Limited : 35|1@1+ (1,0) [0|1] "" STM32G474_TRQI
 SG_ OP_Steer_Max_Limited : 36|1@1+ (1,0) [0|1] "" STM32G474_TRQI
 SG_ OP_OutTq_Limited : 37|1@1+ (1,0) [0|1] "" STM32G474_TRQI
 SG_ Torque_Counter : 40|4@1+ (1,0) [0|15] "" STM32G474_TRQI
 SG_ Torque_Checksum : 48|8@1+ (1,0) [0|255] "" STM32G474_TRQI

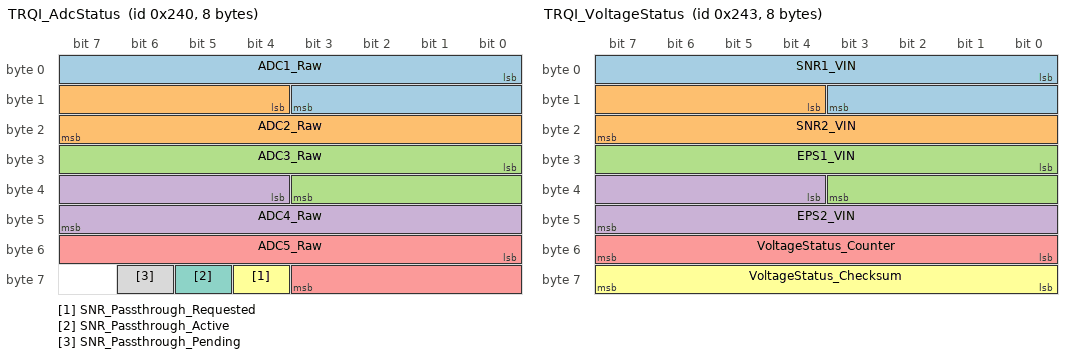
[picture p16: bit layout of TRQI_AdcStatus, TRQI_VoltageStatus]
BO_ 576 TRQI_AdcStatus: 8 STM32G474_TRQI
 SG_ ADC1_Raw : 0|12@1+ (1,0) [0|4095] "code" CAN_Host
 SG_ ADC2_Raw : 12|12@1+ (1,0) [0|4095] "code" CAN_Host
 SG_ ADC3_Raw : 24|12@1+ (1,0) [0|4095] "code" CAN_Host
 SG_ ADC4_Raw : 36|12@1+ (1,0) [0|4095] "code" CAN_Host
 SG_ ADC5_Raw : 48|12@1+ (1,0) [0|4095] "code" CAN_Host
 SG_ SNR_Passthrough_Requested : 60|1@1+ (1,0) [0|1] "" CAN_Host
 SG_ SNR_Passthrough_Active : 61|1@1+ (1,0) [0|1] "" CAN_Host
 SG_ SNR_Passthrough_Pending : 62|1@1+ (1,0) [0|1] "" CAN_Host

BO_ 577 TRQI_IOStatus: 8 STM32G474_TRQI
 SG_ DAC1_Code : 0|12@1+ (1,0) [0|4095] "code" CAN_Host
 SG_ DAC2_Code : 12|12@1+ (1,0) [0|4095] "code" CAN_Host
 SG_ EPS_VREF : 24|12@1+ (0.00125,0) [0|5.11875] "V" CAN_Host
 SG_ REL_State : 36|1@1+ (1,0) [0|1] "" CAN_Host
 SG_ RELE_State : 37|1@1+ (1,0) [0|1] "" CAN_Host
 SG_ RC_Minus : 38|1@1+ (1,0) [0|1] "" CAN_Host
 SG_ RC_Plus : 39|1@1+ (1,0) [0|1] "" CAN_Host
 SG_ Delta_Dlc_Error : 40|1@1+ (1,0) [0|1] "" CAN_Host
 SG_ Delta_Mismatch_Error : 41|1@1+ (1,0) [0|1] "" CAN_Host
 SG_ Delta_Checksum_Error : 42|1@1+ (1,0) [0|1] "" CAN_Host
 SG_ CAN_WDG_TIMO : 43|1@1+ (1,0) [0|1] "" CAN_Host
 SG_ IOStatus_Counter : 44|4@1+ (1,0) [0|15] "" CAN_Host
 SG_ SNR_Pair_Error : 48|1@1+ (1,0) [0|1] "" CAN_Host
 SG_ EPS_Pair_Error : 49|1@1+ (1,0) [0|1] "" CAN_Host
 SG_ Delta_Counter_Error : 50|1@1+ (1,0) [0|1] "" CAN_Host
 SG_ Output_Range_Error : 51|1@1+ (1,0) [0|1] "" CAN_Host
 SG_ DAC_FB_Error : 52|1@1+ (1,0) [0|1] "" CAN_Host
 SG_ RC_State_Error : 53|1@1+ (1,0) [0|1] "" CAN_Host
 SG_ TorqueCal_Valid : 54|1@1+ (1,0) [0|1] "" CAN_Host
 SG_ TorqueCal_Active : 55|1@1+ (1,0) [0|1] "" CAN_Host
 SG_ IOStatus_Checksum : 56|8@1+ (1,0) [0|255] "" CAN_Host

BO_ 578 TRQI_FaultStatus: 8 STM32G474_TRQI
 SG_ Immediate_Disengage_Error : 0|1@1+ (1,0) [0|1] "" CAN_Host
 SG_ Any_TRQI_Limit : 1|1@1+ (1,0) [0|1] "" CAN_Host
 SG_ Diagnostic_Safe_State_Pending : 2|1@1+ (1,0) [0|1] "" CAN_Host
 SG_ NonImmediate_Disengage_Pending : 3|1@1+ (1,0) [0|1] "" CAN_Host
 SG_ Transient_Error_Hold : 4|1@1+ (1,0) [0|1] "" CAN_Host
 SG_ Commanded_Safe_State : 5|1@1+ (1,0) [0|1] "" CAN_Host
 SG_ CAN_Error : 6|1@1+ (1,0) [0|1] "" CAN_Host
 SG_ NonImmediate_Disengage_Error : 7|1@1+ (1,0) [0|1] "" CAN_Host
 SG_ Watchdog_Timeout_Error : 8|1@1+ (1,0) [0|1] "" CAN_Host
 SG_ Abs_Dlc_Error : 9|1@1+ (1,0) [0|1] "" CAN_Host
 SG_ Abs_Mode_Error : 10|1@1+ (1,0) [0|1] "" CAN_Host
 SG_ Delta_Dlc_Error_Detail : 11|1@1+ (1,0) [0|1] "" CAN_Host
 SG_ Delta_Mismatch_Error_Detail : 12|1@1+ (1,0) [0|1] "" CAN_Host
 SG_ Delta_Checksum_Error_Detail : 13|1@1+ (1,0) [0|1] "" CAN_Host
 SG_ Delta_Counter_Error_Detail : 14|1@1+ (1,0) [0|1] "" CAN_Host
 SG_ Delta_Mode_Error : 15|1@1+ (1,0) [0|1] "" CAN_Host
 SG_ Torque_Dlc_Error : 16|1@1+ (1,0) [0|1] "" CAN_Host
 SG_ Torque_Checksum_Error : 17|1@1+ (1,0) [0|1] "" CAN_Host
 SG_ Torque_Complement_Error : 18|1@1+ (1,0) [0|1] "" CAN_Host
 SG_ Torque_Counter_Error : 19|1@1+ (1,0) [0|1] "" CAN_Host
 SG_ Torque_Stale_Speed_Error : 20|1@1+ (1,0) [0|1] "" CAN_Host
 SG_ Torque_Sign_Flip_Error : 21|1@1+ (1,0) [0|1] "" CAN_Host
 SG_ Torque_Step_Error : 22|1@1+ (1,0) [0|1] "" CAN_Host
 SG_ SNR_Pair_Error_Detail : 23|1@1+ (1,0) [0|1] "" CAN_Host
 SG_ EPS_Pair_Error_Detail : 24|1@1+ (1,0) [0|1] "" CAN_Host
 SG_ DAC_FB_Error_Detail : 25|1@1+ (1,0) [0|1] "" CAN_Host
 SG_ RC_State_Error_Detail : 26|1@1+ (1,0) [0|1] "" CAN_Host
 SG_ CAN_RX_FIFO_Lost_Error : 27|1@1+ (1,0) [0|1] "" CAN_Host
 SG_ CAN_Controller_Error : 28|1@1+ (1,0) [0|1] "" CAN_Host
 SG_ CAN_TX_Drop_Error : 29|1@1+ (1,0) [0|1] "" CAN_Host
 SG_ CAN_RX_Overrun_Error : 30|1@1+ (1,0) [0|1] "" CAN_Host
 SG_ CAN_Bus_Off_Error : 31|1@1+ (1,0) [0|1] "" CAN_Host
 SG_ DAC_Output_Clamp_Limit : 32|1@1+ (1,0) [0|1] "" CAN_Host
 SG_ Torque_Demand_Clamp_Limit : 33|1@1+ (1,0) [0|1] "" CAN_Host
 SG_ Delta_Demand_Clamp_Limit : 34|1@1+ (1,0) [0|1] "" CAN_Host
 SG_ Abs_DAC_Code_Clamp_Limit : 35|1@1+ (1,0) [0|1] "" CAN_Host
 SG_ Abs_Midpoint_Clamp_Limit : 36|1@1+ (1,0) [0|1] "" CAN_Host
 SG_ OP_Steer_Delta_Up_Limit : 37|1@1+ (1,0) [0|1] "" CAN_Host
 SG_ OP_Steer_Delta_Down_Limit : 38|1@1+ (1,0) [0|1] "" CAN_Host
 SG_ OP_Steer_Max_Limit : 39|1@1+ (1,0) [0|1] "" CAN_Host
 SG_ OP_OutTq_Limit : 40|1@1+ (1,0) [0|1] "" CAN_Host
 SG_ Host_Command_Limited : 41|1@1+ (1,0) [0|1] "" CAN_Host
 SG_ FaultStatus_Counter : 48|8@1+ (1,0) [0|255] "" CAN_Host
 SG_ FaultStatus_Checksum : 56|8@1+ (1,0) [0|255] "" CAN_Host

BO_ 579 TRQI_VoltageStatus: 8 STM32G474_TRQI
 SG_ SNR1_VIN : 0|12@1+ (0.00125,0) [0|5.11875] "V" CAN_Host
 SG_ SNR2_VIN : 12|12@1+ (0.00125,0) [0|5.11875] "V" CAN_Host
 SG_ EPS1_VIN : 24|12@1+ (0.00125,0) [0|5.11875] "V" CAN_Host
 SG_ EPS2_VIN : 36|12@1+ (0.00125,0) [0|5.11875] "V" CAN_Host
 SG_ VoltageStatus_Counter : 48|8@1+ (1,0) [0|255] "" CAN_Host
 SG_ VoltageStatus_Checksum : 56|8@1+ (1,0) [0|255] "" CAN_Host

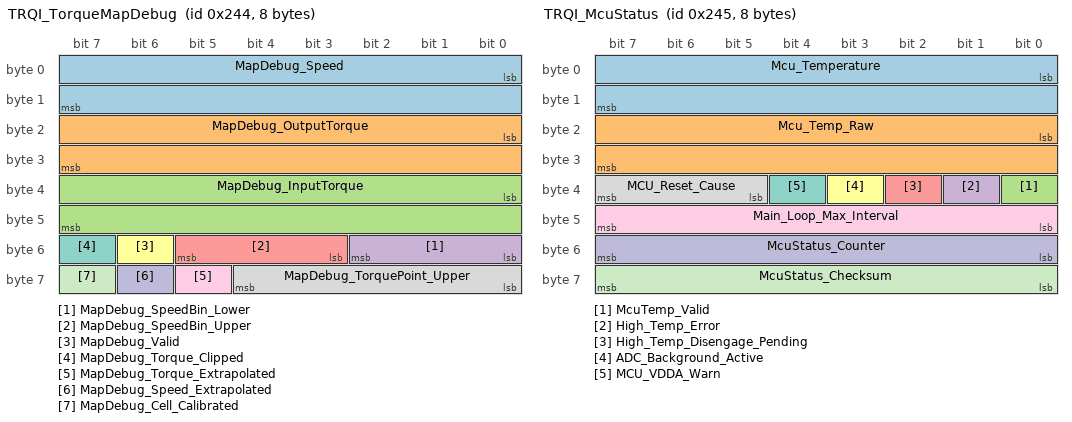
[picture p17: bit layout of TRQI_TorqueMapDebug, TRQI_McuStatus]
BO_ 580 TRQI_TorqueMapDebug: 8 STM32G474_TRQI
 SG_ MapDebug_Speed : 0|16@1+ (0.1,0) [0|6553.5] "km/h" CAN_Host
 SG_ MapDebug_OutputTorque : 16|16@1- (1,0) [-32768|32767] "Ncm" CAN_Host
 SG_ MapDebug_InputTorque : 32|16@1- (1,0) [-32768|32767] "Ncm" CAN_Host
 SG_ MapDebug_SpeedBin_Lower : 48|3@1+ (1,0) [0|7] "" CAN_Host
 SG_ MapDebug_SpeedBin_Upper : 51|3@1+ (1,0) [0|7] "" CAN_Host
 SG_ MapDebug_Valid : 54|1@1+ (1,0) [0|1] "" CAN_Host
 SG_ MapDebug_Torque_Clipped : 55|1@1+ (1,0) [0|1] "" CAN_Host
 SG_ MapDebug_TorquePoint_Upper : 56|5@1+ (1,0) [0|31] "" CAN_Host
 SG_ MapDebug_Torque_Extrapolated : 61|1@1+ (1,0) [0|1] "" CAN_Host
 SG_ MapDebug_Speed_Extrapolated : 62|1@1+ (1,0) [0|1] "" CAN_Host
 SG_ MapDebug_Cell_Calibrated : 63|1@1+ (1,0) [0|1] "" CAN_Host

BO_ 581 TRQI_McuStatus: 8 STM32G474_TRQI
 SG_ Mcu_Temperature : 0|16@1- (0.1,0) [-3276.8|3276.7] "degC" CAN_Host
 SG_ Mcu_Temp_Raw : 16|16@1+ (1,0) [0|65535] "code" CAN_Host
 SG_ McuTemp_Valid : 32|1@1+ (1,0) [0|1] "" CAN_Host
 SG_ High_Temp_Error : 33|1@1+ (1,0) [0|1] "" CAN_Host
 SG_ High_Temp_Disengage_Pending : 34|1@1+ (1,0) [0|1] "" CAN_Host
 SG_ ADC_Background_Active : 35|1@1+ (1,0) [0|1] "" CAN_Host
 SG_ MCU_VDDA_Warn : 36|1@1+ (1,0) [0|1] "" CAN_Host
 SG_ MCU_Reset_Cause : 37|3@1+ (1,0) [0|7] "" CAN_Host
 SG_ Main_Loop_Max_Interval : 40|8@1+ (1,0) [0|255] "ms" CAN_Host
 SG_ McuStatus_Counter : 48|8@1+ (1,0) [0|255] "" CAN_Host
 SG_ McuStatus_Checksum : 56|8@1+ (1,0) [0|255] "" CAN_Host

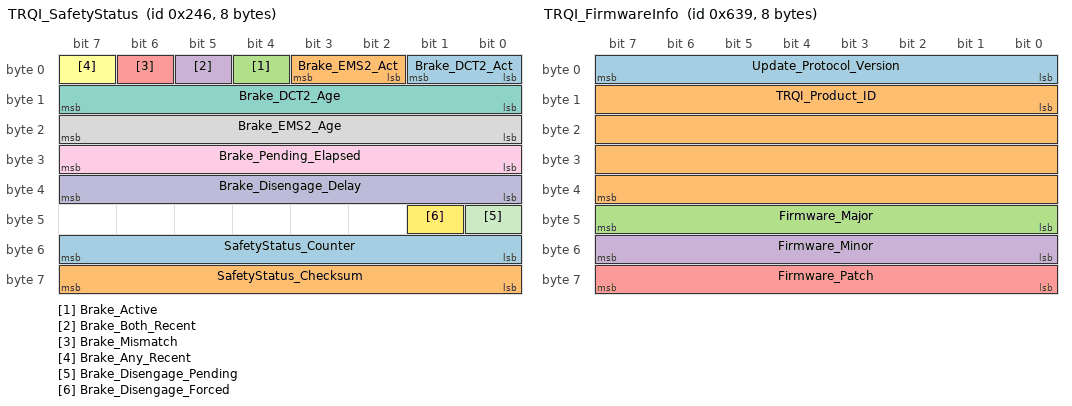
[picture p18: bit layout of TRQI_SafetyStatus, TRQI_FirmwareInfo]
BO_ 582 TRQI_SafetyStatus: 8 STM32G474_TRQI
 SG_ Brake_DCT2_Act : 0|2@1+ (1,0) [0|3] "" CAN_Host
 SG_ Brake_EMS2_Act : 2|2@1+ (1,0) [0|3] "" CAN_Host
 SG_ Brake_Active : 4|1@1+ (1,0) [0|1] "" CAN_Host
 SG_ Brake_Both_Recent : 5|1@1+ (1,0) [0|1] "" CAN_Host
 SG_ Brake_Mismatch : 6|1@1+ (1,0) [0|1] "" CAN_Host
 SG_ Brake_Any_Recent : 7|1@1+ (1,0) [0|1] "" CAN_Host
 SG_ Brake_DCT2_Age : 8|8@1+ (1,0) [0|255] "ms" CAN_Host
 SG_ Brake_EMS2_Age : 16|8@1+ (1,0) [0|255] "ms" CAN_Host
 SG_ Brake_Pending_Elapsed : 24|8@1+ (1,0) [0|255] "ms" CAN_Host
 SG_ Brake_Disengage_Delay : 32|8@1+ (10,0) [0|2550] "ms" CAN_Host
 SG_ Brake_Disengage_Pending : 40|1@1+ (1,0) [0|1] "" CAN_Host
 SG_ Brake_Disengage_Forced : 41|1@1+ (1,0) [0|1] "" CAN_Host
 SG_ SafetyStatus_Counter : 48|8@1+ (1,0) [0|255] "" CAN_Host
 SG_ SafetyStatus_Checksum : 56|8@1+ (1,0) [0|255] "" CAN_Host

BO_ 1593 TRQI_FirmwareInfo: 8 STM32G474_TRQI
 SG_ Update_Protocol_Version : 0|8@1+ (1,0) [0|255] "" CAN_Host
 SG_ TRQI_Product_ID : 8|32@1+ (1,0) [0|4294967295] "" CAN_Host
 SG_ Firmware_Major : 40|8@1+ (1,0) [0|255] "" CAN_Host
 SG_ Firmware_Minor : 48|8@1+ (1,0) [0|255] "" CAN_Host
 SG_ Firmware_Patch : 56|8@1+ (1,0) [0|255] "" CAN_Host

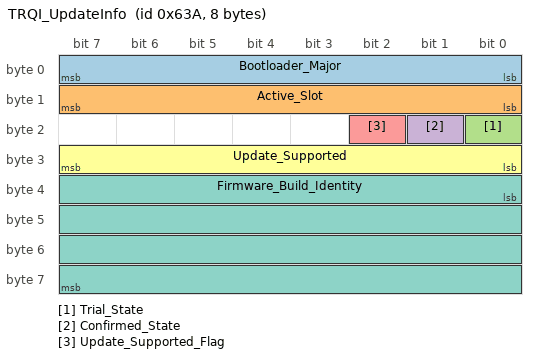
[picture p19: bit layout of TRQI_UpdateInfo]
BO_ 1594 TRQI_UpdateInfo: 8 STM32G474_TRQI
 SG_ Bootloader_Major : 0|8@1+ (1,0) [0|255] "" CAN_Host
 SG_ Active_Slot : 8|8@1+ (1,0) [0|2] "" CAN_Host
 SG_ Trial_State : 16|1@1+ (1,0) [0|1] "" CAN_Host
 SG_ Confirmed_State : 17|1@1+ (1,0) [0|1] "" CAN_Host
 SG_ Update_Supported_Flag : 18|1@1+ (1,0) [0|1] "" CAN_Host
 SG_ Update_Supported : 24|8@1+ (1,0) [0|1] "" CAN_Host
 SG_ Firmware_Build_Identity : 32|32@1+ (1,0) [0|4294967295] "" CAN_Host

BO_ 1595 TRQI_UpdateCompatibility: 8 STM32G474_TRQI
 SG_ Bootloader_Version : 0|32@1+ (1,0) [0|4294967295] "" CAN_Host
 SG_ Security_Version : 32|32@1+ (1,0) [0|4294967295] "" CAN_Host

BO_ 1596 TRQI_BootDiagnostic: 8 STM32G474_TRQI
 SG_ Last_Boot_Error : 0|32@1+ (1,0) [0|4294967295] "" CAN_Host
 SG_ Reset_Flags : 32|32@1+ (1,0) [0|4294967295] "" CAN_Host

CM_ BO_ 560 "Absolute DAC, shared midpoint, and relay command. DAC1_Code and DAC2_Code are raw 12-bit DAC codes. Midpoint_InputVoltage is the external input voltage before halving for the DAC center; SaveToNVM stores that midpoint to flash.";
CM_ BO_ 561 "Differential DAC command matching terminal SET/DAC behavior. DAC_Delta and DAC_Delta_Redundant are signed little-endian and must match, byte4 carries relay commands plus openpilot limit-hit bits including OP_OutTq, Delta_Counter is a 4-bit rolling counter in byte5 bits0..3 that is sequence-checked modulo 16 after the first valid frame, and Delta_Checksum is CRC-8 over id_lo, id_hi, and bytes0..5 with polynomial 0x07 and init 0x00.";
CM_ BO_ 562 "Desired EPS output torque command. Torque_Demand uses the low 12 bits of bytes0..1 as a signed Ncm output-torque demand, Torque_Demand_Complement carries the 12-bit ones-complement of that raw field in bytes2..3, byte4 carries relay commands plus openpilot limit-hit bits including OP_OutTq, Torque_Counter is a 4-bit rolling counter in byte5 bits0..3 that is sequence-checked modulo 16 across accepted 0x232 frames, and Torque_Checksum is CRC-8 over id_lo, id_hi, and bytes0..5 with polynomial 0x07 and init 0x00. The receiver requires recent forwarded 0x1F1 wheel speed, maps desired output torque to required MDPS input torque with a speed-binned drive-log map, then applies the torque-to-DAC calibration. It rejects stale speed, implausible torque jumps, and large sign flips away from zero; demands above +-1000 Ncm are clipped to +-1000 Ncm and reported with Output_Range_Error.";
CM_ BO_ 576 "ADC1..ADC5 raw 12-bit conversion codes packed into 8 bytes; bits60..62 report SNR passthrough requested, active, and torque-confirm-pending state; bit63 is currently unused.";
CM_ BO_ 577 "Reported DAC output codes packed as two 12-bit fields, EPS_VREF as a 12-bit field at 1.25 mV/LSB, relay and RC input states, TRQI delta-command error flags, watchdog timeout state, a 4-bit IOStatus_Counter, SNR/EPS pair plausibility error bits, Delta_Counter_Error, Output_Range_Error, local DAC feedback and RC state error bits, live torque-calibration state bits, and IOStatus_Checksum. RC_Minus maps PB4, RC_Plus maps PB1.";
CM_ BO_ 578 "Expanded TRQI fault and limiter detail. Byte0 carries immediate/non-immediate disengagement summaries, TRQI-owned limit summary, safe-state, CAN category, and pending-delay bits; bytes1..3 carry individual error bits; bytes4..5 carry TRQI clamp bits and mirrored host limiter bits; byte6 is FaultStatus_Counter; byte7 is CRC-8 over id_lo, id_hi, and bytes0..6 with polynomial 0x07 and init 0x00. Command/diagnostic event details latch until the next valid command; CAN transport event details remain visible during the transient hold window; live diagnostic bits also reflect active status.";
CM_ BO_ 579 "SNR1/SNR2/EPS1/EPS2 input voltages after divider scaling, sent as packed 12-bit values at 1.25 mV/LSB (0..5.11875 V), followed by VoltageStatus_Counter and VoltageStatus_Checksum.";
CM_ BO_ 580 "Latest accepted 0x232 torque-map calculation for debugging. Reports the vehicle speed used, limited EPS output-torque demand, mapped MDPS input torque, speed-bin interpolation indexes, torque-axis point index, and map coverage/extrapolation flags. The frame has no checksum or counter; MapDebug_Valid is cleared outside active torque-map control.";
CM_ BO_ 581 "Slow MCU status. Reports the STM32 internal temperature sensor at 0.1 degC/LSB, the raw temperature ADC code, high-temperature error state, high-temperature non-immediate disengage pending state, ADC/VDDA/reset diagnostics, max main-loop interval since the previous successful 0x245 transmit, McuStatus_Counter, and McuStatus_Checksum. Firmware samples and transmits this frame at 1 Hz.";
CM_ BO_ 582 "Safety interlock status. Reports decoded redundant brake signals from EMS_DCT2 0x081 and EMS2 0x329, brake signal freshness/mismatch, the firmware backup brake-disengage pending/forced state, brake signal ages, pending elapsed time, configured brake override delay, SafetyStatus_Counter, and SafetyStatus_Checksum.";
CM_ BO_ 1593 "Application firmware identity and CAN-update protocol support, transmitted at 10 Hz.";
CM_ BO_ 1594 "Application boot context and build identity, transmitted at 10 Hz. Active slot values: 1=A, 2=B.";
CM_ BO_ 1595 "Full bootloader compatibility and independent security/rollback version, transmitted at 10 Hz.";
CM_ BO_ 1596 "Last durable boot outcome and raw STM32 RCC reset flags captured by the bootloader, transmitted at 1 Hz.";

CM_ SG_ 560 DAC1_Code "Raw 12-bit DAC code 0..4095. DAC1 is the project DAC1 label mapped to PA5 / DAC_CHANNEL_2; about 2048 is midscale in the 0..5 V domain.";
CM_ SG_ 560 DAC2_Code "Raw 12-bit DAC code 0..4095. DAC2 is the project DAC2 label mapped to PA4 / DAC_CHANNEL_1; about 2048 is midscale in the 0..5 V domain.";
CM_ SG_ 561 DAC_Delta "Signed raw DAC-count offset around the active midpoint; this is in code counts, not volts.";
CM_ SG_ 561 DAC_Delta_Redundant "Redundant copy of DAC_Delta; it must match DAC_Delta exactly for the command to be accepted.";
CM_ SG_ 561 Delta_Counter "4-bit rolling counter carried in byte5 bits0..3 for 0x231; after the first valid delta frame the receiver expects the next modulo-16 value.";
CM_ SG_ 562 Torque_Demand "Signed desired EPS output torque demand in Ncm carried in the low 12 bits of bytes0..1. Accepted 0x232 frames are mapped through recent 0x1F1 speed into required MDPS input torque, then converted through the built-in or live torque-to-DAC calibration into absolute DAC1/DAC2 outputs.";
CM_ SG_ 562 Torque_Demand_Complement "12-bit ones-complement redundancy for Torque_Demand. It is encoded as Torque_Demand raw12 XOR 0x0FFF in the low 12 bits of bytes2..3.";
CM_ SG_ 562 OP_Steer_Delta_Up_Limited "Set by openpilot when the TRQI torque command was clipped by the openpilot STEER_DELTA_UP limit before transmission.";
CM_ SG_ 562 OP_Steer_Delta_Down_Limited "Set by openpilot when the TRQI torque command was clipped by the openpilot STEER_DELTA_DOWN limit before transmission.";
CM_ SG_ 562 OP_Steer_Max_Limited "Set by openpilot when the TRQI torque command was clipped by the openpilot STEER_MAX/MAX_STEERING_TQ limit before transmission.";
CM_ SG_ 562 OP_OutTq_Limited "Set by openpilot while measured VSM2.CR_Mdps_OutTq exceeds the configured threshold.";
CM_ SG_ 562 Torque_Counter "4-bit rolling counter carried in byte5 bits0..3 for 0x232; after the first valid torque frame the receiver expects the next modulo-16 value.";
CM_ SG_ 562 Torque_Checksum "8-bit CRC of the 0x232 message over id_lo, id_hi, and bytes0..5 using polynomial 0x07 and init 0x00.";
CM_ SG_ 576 ADC1_Raw "Raw 12-bit ADC conversion code 0..4095 from PB15 / SNR1 before divider scaling to input volts.";
CM_ SG_ 576 ADC2_Raw "Raw 12-bit ADC conversion code 0..4095 from PB13 / SNR2 before divider scaling to input volts.";
CM_ SG_ 576 ADC3_Raw "Raw 12-bit ADC conversion code 0..4095 from PA1 / EPS1 before divider scaling to input volts.";
CM_ SG_ 576 ADC4_Raw "Raw 12-bit ADC conversion code 0..4095 from PA2 / EPS2 before divider scaling to input volts.";
CM_ SG_ 576 ADC5_Raw "Raw 12-bit ADC conversion code 0..4095 from PA8 / EPS_VREF before divider scaling to input volts.";
CM_ SG_ 577 SNR_Pair_Error "Set when the SNR pair differs by more than the configured plausibility bound in distance from EPS_VREF/2, or when both SNR signals move to the same side of EPS_VREF/2 once meaningfully away from center. Starts the diagnostic safe-state delay.";
CM_ SG_ 577 EPS_Pair_Error "Set when the EPS pair differs by more than the configured plausibility bound in distance from EPS_VREF/2, or when both EPS signals move to the same side of EPS_VREF/2 once meaningfully away from center. Starts the diagnostic safe-state delay.";
CM_ SG_ 577 DAC1_Code "Reported raw 12-bit DAC code 0..4095. DAC1 is the project DAC1 label mapped to PA5 / DAC_CHANNEL_2; about 2048 is midscale in the 0..5 V domain.";
CM_ SG_ 577 DAC2_Code "Reported raw 12-bit DAC code 0..4095. DAC2 is the project DAC2 label mapped to PA4 / DAC_CHANNEL_1; about 2048 is midscale in the 0..5 V domain.";
CM_ SG_ 560 SaveToNVM "When set, the midpoint value is saved to internal flash.";
CM_ SG_ 561 OP_Steer_Delta_Up_Limited "Set by openpilot when the TRQI command was clipped by the openpilot STEER_DELTA_UP limit before transmission.";
CM_ SG_ 561 OP_Steer_Delta_Down_Limited "Set by openpilot when the TRQI command was clipped by the openpilot STEER_DELTA_DOWN limit before transmission.";
CM_ SG_ 561 OP_Steer_Max_Limited "Set by openpilot when the TRQI command was clipped by the openpilot STEER_MAX/MAX_STEERING_TQ limit before transmission.";
CM_ SG_ 561 OP_OutTq_Limited "Set by openpilot while measured VSM2.CR_Mdps_OutTq exceeds the configured threshold.";
CM_ SG_ 561 Delta_Checksum "8-bit CRC of the 0x231 message over id_lo, id_hi, and bytes0..5 using polynomial 0x07 and init 0x00.";
CM_ SG_ 577 RC_Minus "Digital input PB4 / RC-.";
CM_ SG_ 577 RC_Plus "Digital input PB1 / RC+.";
CM_ SG_ 577 Delta_Dlc_Error "Set when the last TRQI delta frame was rejected because DLC was shorter than 7 bytes.";
CM_ SG_ 577 Delta_Mismatch_Error "Set when the last TRQI delta frame was rejected because DAC_Delta and DAC_Delta_Redundant did not match.";
CM_ SG_ 577 Delta_Checksum_Error "Set when the last TRQI delta frame was rejected because Delta_Checksum did not match the computed CRC-8 value.";
CM_ SG_ 577 CAN_WDG_TIMO "Set when the TRQI command watchdog timed out after 500 ms without a valid 0x230, 0x231, or 0x232 command; outputs are forced to neutral center and both relays are driven off.";
CM_ SG_ 577 Delta_Counter_Error "Set when the last TRQI delta frame was rejected because Delta_Counter was not the expected next modulo-16 value; the receiver resynchronizes to the received counter.";
CM_ SG_ 577 IOStatus_Counter "4-bit rolling counter incremented on each successful 0x241 transmit.";
CM_ SG_ 577 Output_Range_Error "Set when an absolute, delta, or torque TRQI command would drive DAC1 or DAC2 outside the allowed 1.2..3.5 V output window, or when a 0x232 output-torque demand exceeded +-1000 Ncm, and the firmware had to clamp the output.";
CM_ SG_ 577 DAC_FB_Error "Set when the local CANCTR DAC feedback check is active because EPS1/EPS2 do not match the applied DAC outputs within the configured thresholds.";
CM_ SG_ 577 RC_State_Error "Set when the local CANCTR RC state check is active because PB4/PB1 do not match the expected relay-state combination.";
CM_ SG_ 577 TorqueCal_Valid "Set when a live PC4 torque calibration has completed successfully and its RAM map is valid.";
CM_ SG_ 577 TorqueCal_Active "Set while a live PC4 torque calibration capture is currently running.";
CM_ SG_ 577 IOStatus_Checksum "8-bit CRC of the 0x241 message over id_lo, id_hi, and bytes0..6 using polynomial 0x07 and init 0x00.";
CM_ SG_ 578 Immediate_Disengage_Error "Set when an active individual error bit is in the immediate-disengage mask. Includes watchdog, command integrity/mode faults, Torque_Sign_Flip, DAC feedback, RC state, SNR/EPS pair faults, and CAN bus-off. These do not get a long driver-warning grace window once confirmed.";
CM_ SG_ 578 Any_TRQI_Limit "Set when any TRQI-owned limiter/clamp bit is active. Mirrored openpilot/host limiter bits do not set this summary.";
CM_ SG_ 578 Diagnostic_Safe_State_Pending "Set while a confirmed DAC feedback, RC state, SNR pair, or EPS pair error is waiting for the 100 ms diagnostic safe-state delay to expire.";
CM_ SG_ 578 NonImmediate_Disengage_Pending "Set while a non-immediate disengagement fault is in its grace window. Current firmware uses this for CAN RX/controller non-immediate faults with a 1000 ms grace and high MCU temperature with a 10 s grace; watchdog and immediate diagnostics still override it.";
CM_ SG_ 578 Transient_Error_Hold "Set while the local transient error hold is active for LED/diagnostic visibility.";
CM_ SG_ 578 Commanded_Safe_State "Set when the latest valid 0x230/0x231/0x232 control command requested safe state by not commanding both REL and RELE; clears on the next valid active command or mode reset.";
CM_ SG_ 578 CAN_Error "Set when any CAN transport/controller detail bit is active.";
CM_ SG_ 578 NonImmediate_Disengage_Error "Set when an active individual error bit is in the non-immediate disengage mask, or when High_Temp_Error is active in 0x245. Includes Torque_Stale_Speed, Torque_Step, CAN_RX_FIFO_Lost, CAN_Controller, CAN_RX_Overrun, and high MCU temperature. Some non-immediate classes may still be forced safe by the generic control-fault path until a degraded-control grace mode is implemented.";
CM_ SG_ 578 Watchdog_Timeout_Error "Set when the 500 ms CANCTR command watchdog has timed out.";
CM_ SG_ 578 Abs_Dlc_Error "Set when a 0x230 absolute command was shorter than the required 7 bytes.";
CM_ SG_ 578 Abs_Mode_Error "Set when a 0x230 absolute command was rejected because torque mode was active.";
CM_ SG_ 578 Delta_Dlc_Error_Detail "Set when a 0x231 delta command was shorter than the required 7 bytes.";
CM_ SG_ 578 Delta_Mismatch_Error_Detail "Set when a 0x231 delta command redundant delta did not match the primary delta.";
CM_ SG_ 578 Delta_Checksum_Error_Detail "Set when a 0x231 delta command checksum failed.";
CM_ SG_ 578 Delta_Counter_Error_Detail "Set when a 0x231 delta command counter was repeated, too old, or skipped farther than the allowed tolerance.";
CM_ SG_ 578 Delta_Mode_Error "Set when a 0x231 delta command was rejected because torque mode was active.";
CM_ SG_ 578 Torque_Dlc_Error "Set when a 0x232 torque command was shorter than the required 7 bytes.";
CM_ SG_ 578 Torque_Checksum_Error "Set when a 0x232 torque command checksum failed.";
CM_ SG_ 578 Torque_Complement_Error "Set when a 0x232 torque command 12-bit complement did not match Torque_Demand.";
CM_ SG_ 578 Torque_Counter_Error "Set when a 0x232 torque command counter was repeated, too old, or skipped farther than the allowed tolerance.";
CM_ SG_ 578 Torque_Stale_Speed_Error "Set when a 0x232 torque command was rejected because no recent forwarded 0x1F1 wheel speed was available.";
CM_ SG_ 578 Torque_Sign_Flip_Error "Set when a 0x232 torque command was rejected for a large sign flip away from zero.";
CM_ SG_ 578 Torque_Step_Error "Set when a 0x232 torque command was rejected for exceeding the allowed torque step/rate guard.";
CM_ SG_ 578 SNR_Pair_Error_Detail "Set when the SNR pair plausibility check is active, or latched as the cause of a diagnostic safe-state transition.";
CM_ SG_ 578 EPS_Pair_Error_Detail "Set when the EPS pair plausibility check is active, or latched as the cause of a diagnostic safe-state transition.";
CM_ SG_ 578 DAC_FB_Error_Detail "Set when the DAC feedback check is active, or latched as the cause of a diagnostic safe-state transition.";
CM_ SG_ 578 RC_State_Error_Detail "Set when the RC state check is active, or latched as the cause of a diagnostic safe-state transition.";
CM_ SG_ 578 CAN_RX_FIFO_Lost_Error "Set when FDCAN reports an RX FIFO0 message-lost event while CANCTR is active. Classified as non-immediate; current firmware uses a 1000 ms CAN grace timer while hard faults and watchdog still override it.";
CM_ SG_ 578 CAN_Controller_Error "Set when FDCAN reports a controller/protocol status interrupt while CANCTR is active. Transient/recovered controller errors are non-immediate; bus-off is split to CAN_Bus_Off_Error and immediate.";
CM_ SG_ 578 CAN_TX_Drop_Error "Set when a CANCTR status frame could not be queued after retries. Isolated TX drops are report-only and do not arm the non-immediate disengage timer.";
CM_ SG_ 578 CAN_RX_Overrun_Error "Set when a latest-frame slot was overwritten before the CANCTR frame was processed, or when the local CAN RX queue overflowed and dropped frames. Classified as non-immediate; current firmware uses a 1000 ms CAN grace timer while hard faults and watchdog still override it.";
CM_ SG_ 578 CAN_Bus_Off_Error "Set when FDCAN reports bus-off while CANCTR is active. Classified as immediate because command reception is no longer trustworthy.";
CM_ SG_ 578 DAC_Output_Clamp_Limit "Set when CANCTR clamps DAC1 or DAC2 to the allowed 1.2..3.5 V output window.";
CM_ SG_ 578 Torque_Demand_Clamp_Limit "Set when a 0x232 output torque demand exceeded +-1200 Ncm and was clipped (TRQI firmware 0.2.3 and later).";
CM_ SG_ 578 Delta_Demand_Clamp_Limit "Set when a 0x231 delta command exceeded the raw DAC delta range and was clipped.";
CM_ SG_ 578 Abs_DAC_Code_Clamp_Limit "Set when a 0x230 absolute DAC code exceeded the raw 12-bit DAC range and was clipped.";
CM_ SG_ 578 Abs_Midpoint_Clamp_Limit "Set when a 0x230 midpoint input implied an output midpoint above the 0..5 V DAC domain and was clipped.";
CM_ SG_ 578 OP_Steer_Delta_Up_Limit "Mirrors the latest valid 0x231/0x232 OP_STEER_DELTA_UP limiter flag from the command source.";
CM_ SG_ 578 OP_Steer_Delta_Down_Limit "Mirrors the latest valid 0x231/0x232 OP_STEER_DELTA_DOWN limiter flag from the command source.";
CM_ SG_ 578 OP_Steer_Max_Limit "Mirrors the latest valid 0x231/0x232 OP_STEER_MAX limiter flag from the command source.";
CM_ SG_ 578 OP_OutTq_Limit "Mirrors the latest valid 0x231/0x232 OP_OUTTQ limiter flag from the command source.";
CM_ SG_ 578 Host_Command_Limited "Set when any mirrored openpilot/host limiter flag is active. This reports that the command source clipped the request before TRQI received it; it does not set Any_TRQI_Limit.";
CM_ SG_ 578 FaultStatus_Counter "8-bit counter incremented on each successful 0x242 transmit.";
CM_ SG_ 578 FaultStatus_Checksum "8-bit CRC of the 0x242 message over id_lo, id_hi, and bytes0..6 using polynomial 0x07 and init 0x00.";
CM_ SG_ 576 SNR_Passthrough_Requested "Set when SNR passthrough is requested by the SNR1/SNR2 difference threshold and has not released yet.";
CM_ SG_ 576 SNR_Passthrough_Active "Set while SNR passthrough is blended into the applied DAC output.";
CM_ SG_ 576 SNR_Passthrough_Pending "Set while torque-mode SNR passthrough is waiting for the short anti-spike confirmation window.";
CM_ SG_ 579 VoltageStatus_Counter "8-bit rolling counter incremented on each successful 0x243 transmit.";
CM_ SG_ 579 VoltageStatus_Checksum "8-bit CRC of the 0x243 message over id_lo, id_hi, and bytes0..6 using polynomial 0x07 and init 0x00.";
CM_ SG_ 580 MapDebug_Speed "Vehicle speed used by the latest accepted 0x232 torque-map calculation.";
CM_ SG_ 580 MapDebug_OutputTorque "Limited EPS output torque demand passed into the speed map.";
CM_ SG_ 580 MapDebug_InputTorque "MDPS input torque produced by the speed map before torque-to-DAC conversion.";
CM_ SG_ 580 MapDebug_SpeedBin_Lower "Lower speed-bin row index used for interpolation; equals MapDebug_SpeedBin_Upper when speed is outside or exactly on an endpoint row.";
CM_ SG_ 580 MapDebug_SpeedBin_Upper "Upper speed-bin row index used for interpolation; equals MapDebug_SpeedBin_Lower when speed is outside or exactly on an endpoint row.";
CM_ SG_ 580 MapDebug_Valid "Set when the frame contains a current accepted 0x232 torque-map sample; cleared after safe state, absolute/delta control, or mode reset.";
CM_ SG_ 580 MapDebug_Torque_Clipped "Set when the original 0x232 output torque demand was clipped to +-1000 Ncm before mapping.";
CM_ SG_ 580 MapDebug_TorquePoint_Upper "Upper output-torque point index used on the map torque axis. For endpoint extrapolation this is the endpoint index.";
CM_ SG_ 580 MapDebug_Torque_Extrapolated "Set when the limited output torque is outside the generated map torque-axis range.";
CM_ SG_ 580 MapDebug_Speed_Extrapolated "Set when speed is outside the generated speed-bin center range and the endpoint speed row is used.";
CM_ SG_ 580 MapDebug_Cell_Calibrated "Set when all speed/torque map cells used by the current interpolation are marked calibrated in the generated map.";
CM_ SG_ 581 Mcu_Temperature "STM32 internal temperature sensor value in 0.1 degC/LSB. Firmware clamps the reported value to the signed 16-bit signal range.";
CM_ SG_ 581 Mcu_Temp_Raw "Raw averaged ADC code used for the internal temperature sensor conversion.";
CM_ SG_ 581 McuTemp_Valid "Set after the firmware has taken at least one MCU temperature sample in CANCTR mode.";
CM_ SG_ 581 High_Temp_Error "Set when Mcu_Temperature is >=85.0 degC. Clears when Mcu_Temperature falls to <=80.0 degC.";
CM_ SG_ 581 High_Temp_Disengage_Pending "Set while High_Temp_Error is active and the 10 s non-immediate disengage grace window is running.";
CM_ SG_ 581 ADC_Background_Active "Set while the ADC DMA background sampler is active.";
CM_ SG_ 581 MCU_VDDA_Warn "Set when the VDDA estimate used for temperature conversion is outside 3.0..3.6 V.";
CM_ SG_ 581 MCU_Reset_Cause "Latched reset cause captured at boot before reset flags are cleared.";
CM_ SG_ 581 Main_Loop_Max_Interval "Maximum scheduled main-loop interval in milliseconds since the previous successful 0x245 transmit, saturated at 255 ms.";
CM_ SG_ 581 McuStatus_Counter "8-bit counter incremented on each successful 0x245 transmit.";
CM_ SG_ 581 McuStatus_Checksum "8-bit CRC of the 0x245 message over id_lo, id_hi, and bytes0..6 using polynomial 0x07 and init 0x00.";
CM_ SG_ 582 Brake_DCT2_Act "Raw BRAKE_ACT decoded from EMS_DCT2 0x081 bits6..7. Value 2 means brake pedal active.";
CM_ SG_ 582 Brake_EMS2_Act "Raw BRAKE_ACT decoded from EMS2 0x329 bits32..33. Value 2 means brake pedal active.";
CM_ SG_ 582 Brake_Active "Set only when both redundant brake signals are recent and both report BRAKE_ACT=2.";
CM_ SG_ 582 Brake_Both_Recent "Set when both EMS_DCT2 and EMS2 brake signals have been received within the 250 ms freshness window.";
CM_ SG_ 582 Brake_Mismatch "Set when both brake signals are recent but their raw BRAKE_ACT values do not match.";
CM_ SG_ 582 Brake_Any_Recent "Set when either redundant brake signal is recent.";
CM_ SG_ 582 Brake_Disengage_Pending "Set while brake is active and REL/RELE are still on during the firmware backup brake-disengage grace window.";
CM_ SG_ 582 Brake_Disengage_Forced "Set when the firmware forced safe state because brake remained active and OP/host did not disengage within the configured delay. Clears when the brake signal becomes inactive or stale.";
CM_ SG_ 582 Brake_DCT2_Age "Age of the last valid EMS_DCT2 brake frame, saturated at 255 ms. Reports 255 before any valid EMS_DCT2 brake frame.";
CM_ SG_ 582 Brake_EMS2_Age "Age of the last valid EMS2 brake frame, saturated at 255 ms. Reports 255 before any valid EMS2 brake frame.";
CM_ SG_ 582 Brake_Pending_Elapsed "Elapsed time in the current brake-disengage grace window, saturated at 255 ms. Reports the configured delay after forced disengage.";
CM_ SG_ 582 Brake_Disengage_Delay "Configured firmware backup brake-disengage delay. The current 250 ms delay includes at least 100 ms buffer for OP/host brake-disengagement latency.";
CM_ SG_ 582 SafetyStatus_Counter "8-bit counter incremented on each successful 0x246 transmit.";
CM_ SG_ 582 SafetyStatus_Checksum "8-bit CRC of the 0x246 message over id_lo, id_hi, and bytes0..6 using polynomial 0x07 and init 0x00.";

BA_DEF_ BO_  "GenMsgCycleTime" INT 0 65535;
BA_ "GenMsgCycleTime" BO_ 576 100;
BA_ "GenMsgCycleTime" BO_ 577 100;
BA_ "GenMsgCycleTime" BO_ 578 100;
BA_ "GenMsgCycleTime" BO_ 579 100;
BA_ "GenMsgCycleTime" BO_ 580 100;
BA_ "GenMsgCycleTime" BO_ 581 1000;
BA_ "GenMsgCycleTime" BO_ 582 100;
BA_ "GenMsgCycleTime" BO_ 1593 100;
BA_ "GenMsgCycleTime" BO_ 1594 100;
BA_ "GenMsgCycleTime" BO_ 1595 100;
BA_ "GenMsgCycleTime" BO_ 1596 1000;

VAL_ 560 REL_Cmd 0 "OFF" 1 "ON";
VAL_ 560 RELE_Cmd 0 "OFF" 1 "ON";
VAL_ 560 SaveToNVM 0 "No" 1 "Save";
VAL_ 561 REL_Cmd 0 "OFF" 1 "ON";
VAL_ 561 RELE_Cmd 0 "OFF" 1 "ON";
VAL_ 562 REL_Cmd 0 "OFF" 1 "ON";
VAL_ 562 RELE_Cmd 0 "OFF" 1 "ON";
VAL_ 576 SNR_Passthrough_Requested 0 "OFF" 1 "ON";
VAL_ 576 SNR_Passthrough_Active 0 "OFF" 1 "ON";
VAL_ 576 SNR_Passthrough_Pending 0 "OFF" 1 "ON";
VAL_ 581 MCU_Reset_Cause 0 "UNKNOWN" 1 "PIN" 2 "BOR" 3 "IWDG" 4 "WWDG" 5 "SOFTWARE" 6 "LOW_POWER" 7 "OTHER";
VAL_ 582 Brake_DCT2_Act 0 "NOT_ACTIVE" 1 "RESERVED1" 2 "ACTIVE" 3 "RESERVED3";
VAL_ 582 Brake_EMS2_Act 0 "NOT_ACTIVE" 1 "RESERVED1" 2 "ACTIVE" 3 "RESERVED3";
VAL_ 1594 Active_Slot 0 "UNKNOWN" 1 "A" 2 "B";
VAL_ 577 REL_State 0 "OFF" 1 "ON";
VAL_ 577 RELE_State 0 "OFF" 1 "ON";
VAL_ 577 RC_Minus 0 "LOW" 1 "HIGH";
VAL_ 577 RC_Plus 0 "LOW" 1 "HIGH";
VAL_ 577 Delta_Dlc_Error 0 "OK" 1 "ERROR";
VAL_ 577 Delta_Mismatch_Error 0 "OK" 1 "ERROR";
VAL_ 577 Delta_Checksum_Error 0 "OK" 1 "ERROR";
VAL_ 577 SNR_Pair_Error 0 "OK" 1 "ERROR";
VAL_ 577 EPS_Pair_Error 0 "OK" 1 "ERROR";
VAL_ 577 Delta_Counter_Error 0 "OK" 1 "ERROR";
VAL_ 577 Output_Range_Error 0 "OK" 1 "ERROR";

VAL_ 558 STEER_MODE 0 "Off" 1 "TorqueControl" 2 "RelativeControl" 3 "SoftOff" ;
